VERSION ""

NS_ :

BS_:

BU_: CSDB CSDA HCM TSTR LDCMA LDCMB
VAL_TABLE_ Tracer_Turn_Actv 2 "SEQ B" 1 "SEQ A" 0 "Null" ;
VAL_TABLE_ Front_Fog_Actv 1 "Front Fog ON" 0 "Front Fog OFF" ;
VAL_TABLE_ Mdule1_Fail 1 "LDM is NOK" 0 "LDM is OK" ;
VAL_TABLE_ Hl_Temp_Stat 1 "HL over temperature " 0 "HL temperature OK" ;
VAL_TABLE_ HlHBSegFeedb 3 "At least one segment activated" 2 "Ramping up" 1 "Ramping down" 0 "All deactivated" ;
VAL_TABLE_ Low_Beam_state 1 "Low Beam Active" 0 "Default" ;
VAL_TABLE_ HeadLghtLvlRef_D_Rq 5 "Start partially reference 4" 4 "Start partially reference 3" 3 "Start partially reference 2" 2 "Lvl ref only" 1 "Start full rerence" 0 "No referencing action" ;
VAL_TABLE_ HeadLghtLvl_No_Rq 4095 "Faulty" ;
VAL_TABLE_ Quality_Flag 3 "OK" 2 "Not within specification" 1 "No Data exists" 0 "Faulty" ;
VAL_TABLE_ WfSubstate 5 "Approach" 4 "CourtesyLightDelay" 3 "DoorAjarCourtesyLights" 2 "IllExit" 1 "IllumEntry" 0 "NULL" ;
VAL_TABLE_ WfSuperstate 3 "FAREWELL" 2 "RUNSTART" 1 "WELCOME" 0 "OFF" ;
VAL_TABLE_ Hl_SM_Stat 1 "SM unit failure detected" 0 "SM unit status OK" ;
VAL_TABLE_ Hl_DRL_POS_Stat 1 "DRL_POS unit failure detected" 0 "DRL_POS unit status OK" ;
VAL_TABLE_ Hl_TI_Stat 1 "TI unit failure detected" 0 "TI unit status OK" ;
VAL_TABLE_ Hl_SBL_Stat 1 "SBL unit failure detected" 0 "SBL unit status OK" ;
VAL_TABLE_ Hl_Foregrd_Stat 1 "Foreground unit failure detected" 0 "Foreground unit status OK" ;
VAL_TABLE_ Hl_Pixel_Stat 1 "Pixel unit failure detected" 0 "Pixel unit status OK" ;
VAL_TABLE_ Hl_Fan_B_Stat 1 "Fan failure detected" 0 "Fan status OK" ;
VAL_TABLE_ Mdule1Hl_side_Stat 2 "LDM side detection failed." 1 "LDM detected right side." 0 "LDM detected left side." ;
VAL_TABLE_ Mdule1Hl_Com_Stat 1 "Physical CAN bus com lost" 0 "Physical CAN bus OK" ;
VAL_TABLE_ Mdule1_LB_Pwr_B_Stat 1 "LDM LB power supply power lost" 0 "LDM LB power supply available" ;
VAL_TABLE_ Mdule1_MPwr_B_Stat 1 "LDM main power supply power lost" 0 "LDM main power supply available." ;
VAL_TABLE_ DrlPos_Actv_Rq 2 "DRL intensity" 1 "POS intensity" 0 "OFF" ;
VAL_TABLE_ Turn_Actv_Rq 4 "ON Cycle sequential B" 3 "ON Cycle sequential A" 2 "ON Cycle" 1 "OFF Cycle" 0 "OFF" ;
VAL_TABLE_ Hlspot1_Rq 3 "Spot (only right side)" 2 "Spot (only left side)" 1 "Spot (both sides)" 0 "Not active" ;
VAL_TABLE_ HiBeamHWmde_SED_Rq 2 "Highway mode LHT" 1 "Highway mode RHT" 0 "No highway mode" ;
VAL_TABLE_ HllHBFeedb_D_Stat 4 "Spot (only right side)" 3 "Spot (only left side)" 2 "Spot (Both sides)" 1 "Full HB" 0 "HB off" ;
VAL_TABLE_ HB_D_Rq 6 "Spot (only right side)" 5 "Spot (only left side)" 4 "Spot (both sides)" 3 "Auto full highbeam" 2 "Manual full high beam" 1 "Flash to pass" 0 "No High beam" ;
VAL_TABLE_ TempStat 2 "Overtemperature" 1 "High Temperature" 0 "Status OK" ;
VAL_TABLE_ HlLevelStat 2 "Ref ongoing" 3 "Motor fail" 1 "Ref of stepper motors done" 0 "Ref of stepper motor necessary" ;
VAL_TABLE_ LvLRefRun_D_Req 5 "Start partially reference 4" 4 "Start partially reference 3" 3 "Start partially reference 2" 2 "Start partially reference 1" 1 "Start full rerence" 0 "No referencing action" ;
VAL_TABLE_ Sdlm_D_Rq 13 "Class W" 12 "Class E3" 11 "Class E2" 10 "Class E1" 9 "Class E" 8 "Class C4" 7 "Class C3" 6 "Class C2" 5 "Class C1" 4 "Class V1" 3 "Class V2" 2 "Class V3" 1 "Class V4" 0 "Class C" ;
VAL_TABLE_ MduleLeftFail_B_Stat 3 "Headlamp and LDM failure" 2 "Headlamp failure" 1 "LDM failure" 0 "OK" ;
VAL_TABLE_ MduleConfg_B_Stat 1 "FAULTY" 0 "OK" ;
VAL_TABLE_ HlSpotBrght_Pc_Rq 31 "Faulty" ;
VAL_TABLE_ HlSpotShape_D_Rq 15 "No valid signal" 14 "Shape 15" 13 "Shape 14" 12 "Shape 13" 11 "Shape 12" 10 "Shape 11" 9 "Shape 10" 8 "Shape 9" 7 "Shape 8" 6 "Shape 7" 5 "Shape 6" 4 "Shape 5" 3 "Shape 4" 2 "Shape 3" 1 "Shape 2" 0 "Shape 1" ;
VAL_TABLE_ DblTrgt_An_Rq 2047 "Faulty" ;
VAL_TABLE_ HlSpotTrgt_An_Rq 2047 "FAULT" ;
VAL_TABLE_ UnitlessValue12bit_IncldFaltET 4095 "Faulty" ;
VAL_TABLE_ Faulty_1F 31 "Faulty" ;
VAL_TABLE_ Faulty_7FF 2047 "Faulty" ;

BO_ 3221225472 VECTOR__INDEPENDENT_SIG_MSG: 0 Vector__XXX
 SG_ HeadLghtLvlRghtRef_D_Rq : 0|3@0+ (1,0) [0|7] "" Vector__XXX
 SG_ HeadLghtLvlLeftRef_D_Rq : 0|3@0+ (1,0) [0|7] "" Vector__XXX
 SG_ HeadLghtLvlRight_No_Rq : 0|12@0+ (1,0) [0|4095] "1/2 step" Vector__XXX
 SG_ HeadLghtLvlLeft_No_Rq : 0|12@0+ (1,0) [0|4095] "1/2 step" Vector__XXX
 SG_ HeadLghtDblRght_No_Stat : 0|12@0+ (1,0) [0|4095] "1/2 step" Vector__XXX
 SG_ HeadLghtDblLeft_No_Stat : 0|12@0+ (1,0) [0|4095] "1/2 step" Vector__XXX
 SG_ HeadLghtDblRight_No_Rq : 0|12@0+ (1,0) [0|4095] "1/2 step" Vector__XXX
 SG_ HeadLghtDblLeft_No_Rq : 0|12@0+ (1,0) [0|4095] "1/2 step" Vector__XXX
 SG_ Hlr_Foregrd_Stat : 0|1@0+ (1,0) [0|1] "" Vector__XXX
 SG_ Hll_Foregrd_Stat : 0|1@0+ (1,0) [0|1] "" Vector__XXX
 SG_ Tracer_Turn_Actv_Rq : 0|2@0+ (1,0) [0|3] "SED" Vector__XXX
 SG_ Turn_Deactv_Brght_Rq : 0|8@0+ (0.5,0) [0|100] "%" Vector__XXX
 SG_ LowBeam_Stat : 0|1@0+ (1,0) [0|1] "" Vector__XXX
 SG_ Turn_Actv_Rf_Rq : 0|2@0+ (1,0) [0|3] "" Vector__XXX
 SG_ Turn_Actv_Lf_Rq : 0|2@0+ (1,0) [0|3] "" Vector__XXX
 SG_ HeadLampLoFrOut_B_Stat : 0|1@0+ (1,0) [0|1] "SED" Vector__XXX
 SG_ TurnLampFrOut_B_Stat : 0|1@0+ (1,0) [0|1] "" Vector__XXX
 SG_ HeadLampLoFlOut_B_Stat : 0|1@0+ (1,0) [0|1] "SED" Vector__XXX
 SG_ TurnLampFlOut_B_Stat : 0|1@0+ (1,0) [0|1] "" Vector__XXX

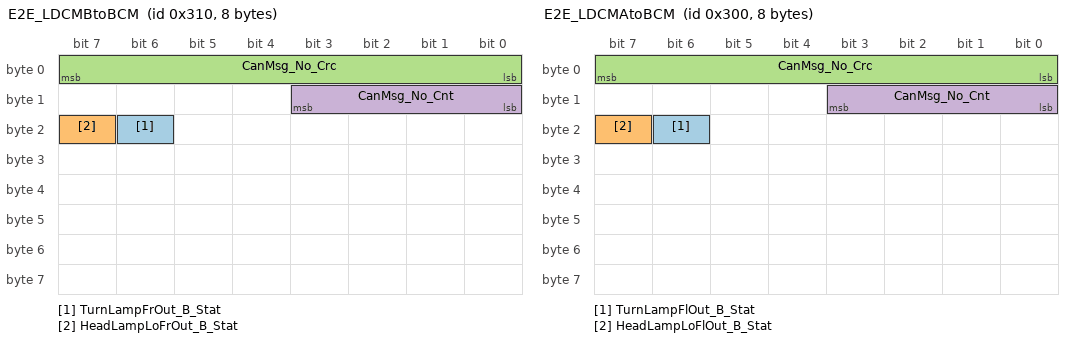
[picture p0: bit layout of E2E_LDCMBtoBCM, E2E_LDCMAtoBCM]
BO_ 784 E2E_LDCMBtoBCM: 8 LDCMB
 SG_ TurnLampFrOut_B_Stat : 22|1@0+ (1,0) [0|1] ""  HCM
 SG_ HeadLampLoFrOut_B_Stat : 23|1@0+ (1,0) [0|1] "SED"  HCM
 SG_ CanMsg_No_Crc : 7|8@0+ (1,0) [0|255] "Unitless" Vector__XXX
 SG_ CanMsg_No_Cnt : 11|4@0+ (1,0) [0|15] "Unitless" Vector__XXX

BO_ 768 E2E_LDCMAtoBCM: 8 LDCMA
 SG_ TurnLampFlOut_B_Stat : 22|1@0+ (1,0) [0|1] ""  HCM
 SG_ HeadLampLoFlOut_B_Stat : 23|1@0+ (1,0) [0|1] "SED"  HCM
 SG_ CanMsg_No_Crc : 7|8@0+ (1,0) [0|255] "Unitless" Vector__XXX
 SG_ CanMsg_No_Cnt : 11|4@0+ (1,0) [0|15] "Unitless" Vector__XXX

BO_ 1553 XCP_TSTRtoLDCMB: 8 TSTR
 SG_ XCP_TSTRtoLDCMB : 7|64@0+ (1,0) [0|1.84467E+019] "unitless"  LDCMB

BO_ 1552 XCP_TSTRtoLDCMA: 8 TSTR
 SG_ XCP_TSTRtoLDCMA : 7|64@0+ (1,0) [0|1.84467E+019] "unitless"  LDCMA

BO_ 1537 XCP_LDCMBtoTSTR: 8 LDCMB
 SG_ XCP_LDCMBtoTSTR : 7|64@0+ (1,0) [0|1.84467E+019] "unitless"  TSTR

BO_ 1536 XCP_LDCMAtoTSTR: 8 LDCMA
 SG_ XCP_LDCMAtoTSTR : 7|64@0+ (1,0) [0|1.84467E+019] "unitless"  TSTR

BO_ 2612224078 PARSEDPushLDCMBtoGWM_ECG: 8 LDCMB
 SG_ PARSEDPushLDCMBtoGWM_ECG : 7|29@0+ (1,0) [0|536870911] "unitless"  HCM

BO_ 2612082904 PARSEDPushFcGWM_ECGtoLDCMB: 8 HCM
 SG_ PARSEDPushFcGWM_ECGtoLDCMB : 7|29@0+ (1,0) [0|536870911] "unitless"  LDCMB

BO_ 2611175502 PARSEDPhysLDCMBtoGWM_ECG: 8 LDCMB
 SG_ PARSEDPhysLDCMBtoGWM_ECG : 7|29@0+ (1,0) [0|536870911] "unitless"  HCM

BO_ 2611034328 PARSEDPhysGWM_ECGtoLDCMB: 8 HCM
 SG_ PARSEDPhysGWM_ECGtoLDCMB : 7|29@0+ (1,0) [0|536870911] "unitless"  LDCMB

BO_ 2610126926 OTAPhysLDCMBtoGWM_ECG: 8 LDCMB
 SG_ OTAPhysLDCMBtoGWM_ECG : 7|29@0+ (1,0) [0|536870911] "unitless"  HCM

BO_ 2609985752 OTAPhysGWM_ECGtoLDCMB: 8 HCM
 SG_ OTAPhysGWM_ECGtoLDCMB : 7|29@0+ (1,0) [0|536870911] "unitless"  LDCMB

BO_ 2612224079 PARSEDPushLDCMAtoGWM_ECG: 8 LDCMA
 SG_ PARSEDPushLDCMAtoGWM_ECG : 7|29@0+ (1,0) [0|536870911] "unitless"  HCM

BO_ 1798 TesterPhysicalReqDev: 8 TSTR
 SG_ TesterPhysicalReqDev : 7|64@0+ (1,0) [0|1.84467E+019] "unitless"  CSDB,CSDA

BO_ 1806 TesterPhysicalResDev: 8 CSDA
 SG_ TesterPhysicalResDev : 7|64@0+ (1,0) [0|1.84467E+019] "unitless"  TSTR

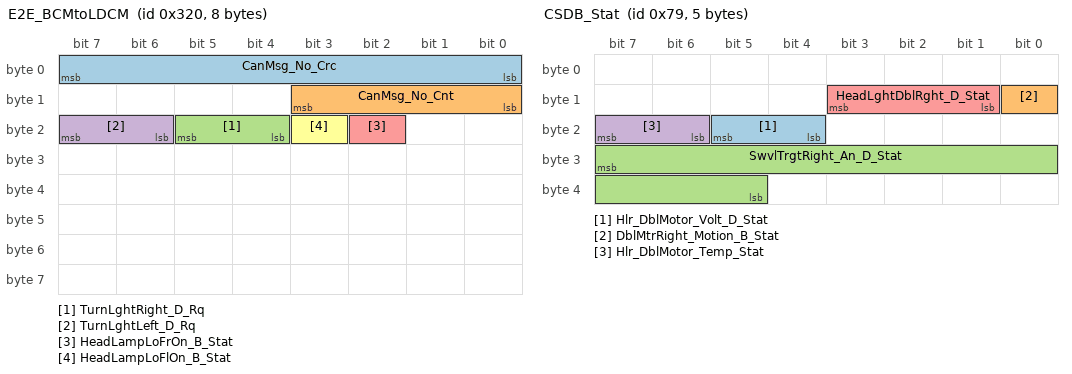
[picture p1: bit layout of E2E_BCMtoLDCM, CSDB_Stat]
BO_ 800 E2E_BCMtoLDCM: 8 HCM
 SG_ CanMsg_No_Crc : 7|8@0+ (1,0) [0|255] "Unitless" Vector__XXX
 SG_ CanMsg_No_Cnt : 11|4@0+ (1,0) [0|15] "Unitless" Vector__XXX
 SG_ TurnLghtRight_D_Rq : 21|2@0+ (1,0) [0|3] "SED"  LDCMA,LDCMB
 SG_ TurnLghtLeft_D_Rq : 23|2@0+ (1,0) [0|3] "SED"  LDCMB,LDCMA
 SG_ HeadLampLoFrOn_B_Stat : 18|1@0+ (1,0) [0|1] "SED"  LDCMA,LDCMB
 SG_ HeadLampLoFlOn_B_Stat : 19|1@0+ (1,0) [0|1] "SED"  LDCMB,LDCMA

BO_ 121 CSDB_Stat: 5 CSDB
 SG_ Hlr_DblMotor_Volt_D_Stat : 21|2@0+ (1,0) [0|3] "" Vector__XXX
 SG_ DblMtrRight_Motion_B_Stat : 8|1@0+ (1,0) [0|1] "" Vector__XXX
 SG_ SwvlTrgtRight_An_D_Stat : 31|11@0+ (0.04,-35) [-35|46.88] "Degrees" Vector__XXX
 SG_ Hlr_DblMotor_Temp_Stat : 23|2@0+ (1,0) [0|3] ""  HCM
 SG_ HeadLghtDblRght_D_Stat : 11|3@0+ (1,0) [0|7] "" Vector__XXX

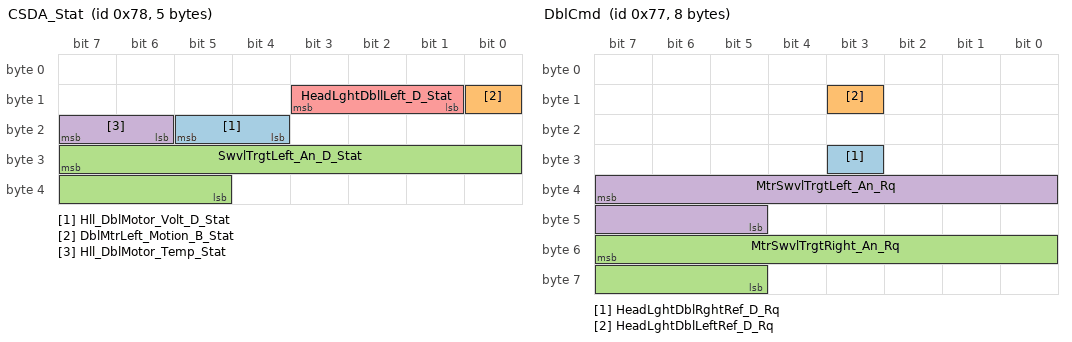
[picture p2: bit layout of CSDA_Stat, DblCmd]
BO_ 120 CSDA_Stat: 5 CSDA
 SG_ Hll_DblMotor_Volt_D_Stat : 21|2@0+ (1,0) [0|3] ""  HCM
 SG_ DblMtrLeft_Motion_B_Stat : 8|1@0+ (1,0) [0|1] "" Vector__XXX
 SG_ SwvlTrgtLeft_An_D_Stat : 31|11@0+ (0.04,-35) [-35|46.88] "Degrees" Vector__XXX
 SG_ Hll_DblMotor_Temp_Stat : 23|2@0+ (1,0) [0|3] "" Vector__XXX
 SG_ HeadLghtDbllLeft_D_Stat : 11|3@0+ (1,0) [0|7] "" Vector__XXX

BO_ 119 DblCmd: 8 HCM
 SG_ HeadLghtDblRghtRef_D_Rq : 27|1@0+ (1,0) [0|1] "" Vector__XXX
 SG_ HeadLghtDblLeftRef_D_Rq : 11|1@0+ (1,0) [0|1] "" Vector__XXX
 SG_ MtrSwvlTrgtRight_An_Rq : 55|11@0+ (0.04,-35) [-35|46.88] "Degrees"  CSDB
 SG_ MtrSwvlTrgtLeft_An_Rq : 39|11@0+ (0.04,-35) [-35|46.88] "Degrees"  CSDA

BO_ 1805 TesterPhysicalResCDSB: 8 CSDB
 SG_ TesterPhysicalResCDSB : 7|64@0+ (1,0) [0|1.84467E+019] "unitless"  TSTR

BO_ 1797 TesterPhysicalReqCDSB: 8 TSTR
 SG_ TesterPhysicalReqCDSB : 7|64@0+ (1,0) [0|1.84467E+019] "unitless"  CSDB

BO_ 1796 TesterPhysicalReqCDSA: 8 TSTR
 SG_ TesterPhysicalReqCDSA : 7|64@0+ (1,0) [0|1.84467E+019] "unitless"  CSDA

BO_ 1804 TesterPhysicalResCDSA: 8 CSDA
 SG_ TesterPhysicalResCDSA : 7|64@0+ (1,0) [0|1.84467E+019] "unitless"  TSTR

BO_ 2611035352 PARSEDPhysGWM_ECGtoLDCMA: 8 HCM
 SG_ PARSEDPhysGWM_ECGtoLDCMA : 7|29@0+ (1,0) [0|536870911] "unitless"  LDCMA

BO_ 2612083928 PARSEDPushFcGWM_ECGtoLDCMA: 8 HCM
 SG_ PARSEDPushFcGWM_ECGtoLDCMA : 7|29@0+ (1,0) [0|536870911] "unitless"  LDCMA

BO_ 2611175503 PARSEDPhysLDCMAtoGWM_ECG: 8 LDCMA
 SG_ PARSEDPhysLDCMAtoGWM_ECG : 7|29@0+ (1,0) [0|536870911] "unitless"  HCM

BO_ 2612002008 PARSEDFuncGWM_ECG_HCM: 8 HCM
 SG_ PARSEDFuncGWM_ECG : 7|29@0+ (1,0) [0|536870911] "unitless"  LDCMB,LDCMA

BO_ 2610126927 OTAPhysLDCMAtoGWM_ECG: 8 LDCMA
 SG_ OTAPhysLDCMAtoGWM_ECG : 7|29@0+ (1,0) [0|536870911] "unitless"  HCM

BO_ 2609986776 OTAPhysGWM_ECGtoLDCMA: 8 HCM
 SG_ OTAPhysGWM_ECGtoLDCMA : 7|29@0+ (1,0) [0|536870911] "unitless"  LDCMA

BO_ 2610953432 OTAFuncGWM_ECG_HCM: 8 HCM
 SG_ OTAFuncGWM_ECG : 7|29@0+ (1,0) [0|536870911] "unitless"  LDCMA,LDCMB

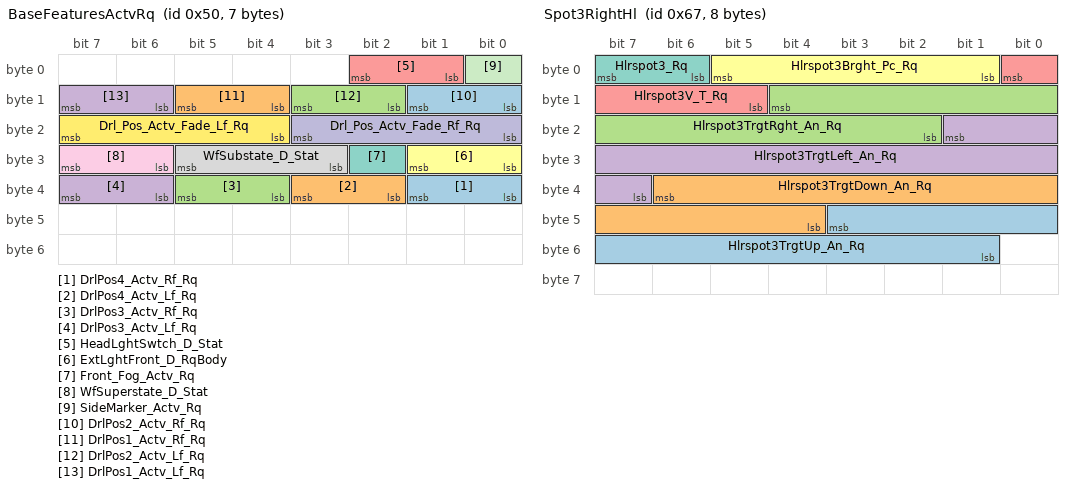
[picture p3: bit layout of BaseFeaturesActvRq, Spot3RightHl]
BO_ 80 BaseFeaturesActvRq: 7 HCM
 SG_ DrlPos4_Actv_Rf_Rq : 33|2@0+ (1,0) [0|3] " "  LDCMB,LDCMA
 SG_ DrlPos4_Actv_Lf_Rq : 35|2@0+ (1,0) [0|3] " "  LDCMB,LDCMA
 SG_ DrlPos3_Actv_Rf_Rq : 37|2@0+ (1,0) [0|3] " "  LDCMB,LDCMA
 SG_ DrlPos3_Actv_Lf_Rq : 39|2@0+ (1,0) [0|3] " "  LDCMB,LDCMA
 SG_ HeadLghtSwtch_D_Stat : 2|2@0+ (1,0) [0|3] " SED"  LDCMB,LDCMA
 SG_ ExtLghtFront_D_RqBody : 25|2@0+ (1,0) [0|3] ""  LDCMB,LDCMA
 SG_ Front_Fog_Actv_Rq : 26|1@0+ (1,0) [0|1] " SED"  LDCMA,LDCMB
 SG_ WfSubstate_D_Stat : 29|3@0+ (1,0) [0|7] ""  LDCMB,LDCMA
 SG_ WfSuperstate_D_Stat : 31|2@0+ (1,0) [0|3] ""  LDCMB,LDCMA
 SG_ Drl_Pos_Actv_Fade_Rf_Rq : 19|4@0+ (200,0) [0|3000] "ms"  LDCMB
 SG_ SideMarker_Actv_Rq : 0|1@0+ (1,0) [0|1] ""  LDCMB,LDCMA
 SG_ Drl_Pos_Actv_Fade_Lf_Rq : 23|4@0+ (200,0) [0|3000] "ms"  LDCMA
 SG_ DrlPos2_Actv_Rf_Rq : 9|2@0+ (1,0) [0|3] " "  LDCMA,LDCMB
 SG_ DrlPos1_Actv_Rf_Rq : 13|2@0+ (1,0) [0|3] " "  LDCMA,LDCMB
 SG_ DrlPos2_Actv_Lf_Rq : 11|2@0+ (1,0) [0|3] " "  LDCMB,LDCMA
 SG_ DrlPos1_Actv_Lf_Rq : 15|2@0+ (1,0) [0|3] " "  LDCMB,LDCMA

BO_ 103 Spot3RightHl: 8 HCM
 SG_ Hlrspot3TrgtUp_An_Rq : 43|11@0+ (0.04,-35) [-35|46.84] "degrees"  LDCMB
 SG_ Hlrspot3TrgtDown_An_Rq : 38|11@0+ (0.04,-35) [-35|46.84] "degrees"  LDCMB
 SG_ Hlrspot3TrgtRght_An_Rq : 12|11@0+ (0.04,-35) [-35|46.84] "degrees"  LDCMB
 SG_ Hlrspot3TrgtLeft_An_Rq : 17|11@0+ (0.04,-35) [-35|46.84] "degrees"  LDCMB
 SG_ Hlrspot3V_T_Rq : 0|4@0+ (200,0) [0|3000] "ms"  LDCMB
 SG_ Hlrspot3Brght_Pc_Rq : 5|5@0+ (3.5,0) [0|105] "percent"  LDCMB
 SG_ Hlrspot3_Rq : 7|2@0+ (1,0) [0|0] ""  LDCMB

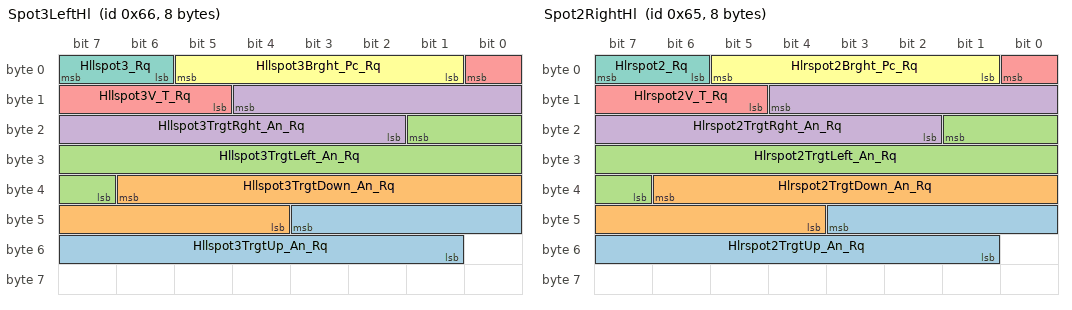
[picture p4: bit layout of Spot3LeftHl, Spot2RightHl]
BO_ 102 Spot3LeftHl: 8 HCM
 SG_ Hllspot3TrgtUp_An_Rq : 43|11@0+ (0.04,-35) [-35|46.84] "degrees"  LDCMA
 SG_ Hllspot3TrgtDown_An_Rq : 38|11@0+ (0.04,-35) [-35|46.84] "degrees"  LDCMA
 SG_ Hllspot3TrgtLeft_An_Rq : 17|11@0+ (0.04,-35) [-35|46.84] "degrees"  LDCMA
 SG_ Hllspot3TrgtRght_An_Rq : 12|11@0+ (0.04,-35) [-35|46.84] "degrees"  LDCMA
 SG_ Hllspot3V_T_Rq : 0|4@0+ (200,0) [0|3000] "ms"  LDCMA
 SG_ Hllspot3Brght_Pc_Rq : 5|5@0+ (3.5,0) [0|105] "percent"  LDCMA
 SG_ Hllspot3_Rq : 7|2@0+ (1,0) [0|3] ""  LDCMA

BO_ 101 Spot2RightHl: 8 HCM
 SG_ Hlrspot2TrgtUp_An_Rq : 43|11@0+ (0.04,-35) [-35|46.84] "degrees"  LDCMB
 SG_ Hlrspot2TrgtDown_An_Rq : 38|11@0+ (0.04,-35) [-35|46.84] "degrees"  LDCMB
 SG_ Hlrspot2TrgtLeft_An_Rq : 17|11@0+ (0.04,-35) [-35|46.84] "degrees"  LDCMB
 SG_ Hlrspot2TrgtRght_An_Rq : 12|11@0+ (0.04,-35) [-35|46.84] "degrees"  LDCMB
 SG_ Hlrspot2V_T_Rq : 0|4@0+ (200,0) [0|3000] "ms"  LDCMB
 SG_ Hlrspot2Brght_Pc_Rq : 5|5@0+ (3.5,0) [0|105] "percent"  LDCMB
 SG_ Hlrspot2_Rq : 7|2@0+ (1,0) [0|0] ""  LDCMB

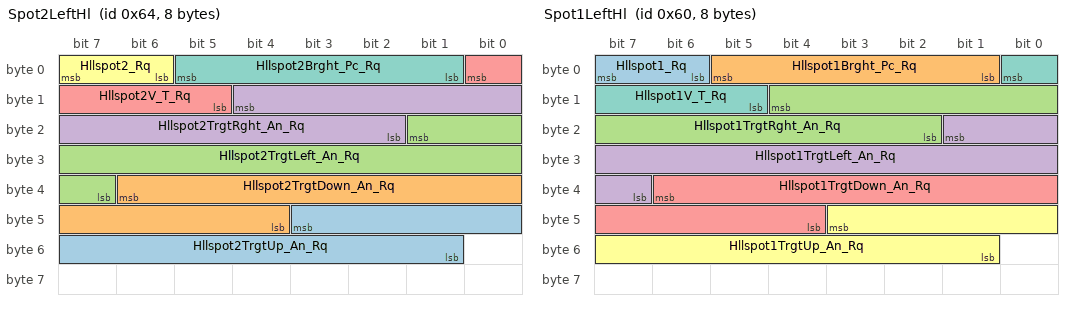
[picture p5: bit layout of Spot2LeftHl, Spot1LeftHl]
BO_ 100 Spot2LeftHl: 8 HCM
 SG_ Hllspot2TrgtUp_An_Rq : 43|11@0+ (0.04,-35) [-35|46.84] "degrees"  LDCMA
 SG_ Hllspot2TrgtDown_An_Rq : 38|11@0+ (0.04,-35) [-35|46.84] "degrees"  LDCMA
 SG_ Hllspot2TrgtLeft_An_Rq : 17|11@0+ (0.04,-35) [-35|46.84] "degrees"  LDCMA
 SG_ Hllspot2TrgtRght_An_Rq : 12|11@0+ (0.04,-35) [-35|46.84] "degrees"  LDCMA
 SG_ Hllspot2V_T_Rq : 0|4@0+ (200,0) [0|3000] "ms"  LDCMA
 SG_ Hllspot2_Rq : 7|2@0+ (1,0) [0|3] ""  LDCMA
 SG_ Hllspot2Brght_Pc_Rq : 5|5@0+ (3.5,0) [0|105] "percent"  LDCMA

BO_ 2015 TesterFunctionalReq_HCM: 8 TSTR
 SG_ TesterFunctionalReq : 7|64@0+ (1,0) [0|1.84467E+019] "unitless"  LDCMA,LDCMB

BO_ 1791 TesterPhysicalResLDCMB: 8 LDCMB
 SG_ TesterPhysicalResLDCMB : 7|64@0+ (1,0) [0|1.84467E+019] "unitless"  TSTR,HCM

BO_ 1790 TesterPhysicalResLDCMA: 8 LDCMA
 SG_ TesterPhysicalResLDCMA : 7|64@0+ (1,0) [0|1.84467E+019] "unitless"  TSTR,HCM

BO_ 1783 TesterPhysicalReqLDCMB: 8 TSTR
 SG_ TesterPhysicalReqLDCMB : 7|64@0+ (1,0) [0|1.84467E+019] "unitless"  LDCMB

BO_ 1782 TesterPhysicalReqLDCMA: 8 TSTR
 SG_ TesterPhysicalReqLDCMA : 7|64@0+ (1,0) [0|1.84467E+019] "unitless"  LDCMA

BO_ 96 Spot1LeftHl: 8 HCM
 SG_ Hllspot1_Rq : 7|2@0+ (1,0) [0|3] ""  LDCMA
 SG_ Hllspot1Brght_Pc_Rq : 5|5@0+ (3.5,0) [0|108.5] "percent"  LDCMA
 SG_ Hllspot1TrgtRght_An_Rq : 12|11@0+ (0.04,-35) [-35|46.84] "degrees"  LDCMA
 SG_ Hllspot1TrgtLeft_An_Rq : 17|11@0+ (0.04,-35) [-35|46.84] "degrees"  LDCMA
 SG_ Hllspot1TrgtDown_An_Rq : 38|11@0+ (0.04,-35) [-35|46.84] "degrees"  LDCMA
 SG_ Hllspot1TrgtUp_An_Rq : 43|11@0+ (0.04,-35) [-35|46.84] "degrees"  LDCMA
 SG_ Hllspot1V_T_Rq : 0|4@0+ (200,0) [0|3000] "ms"  LDCMA

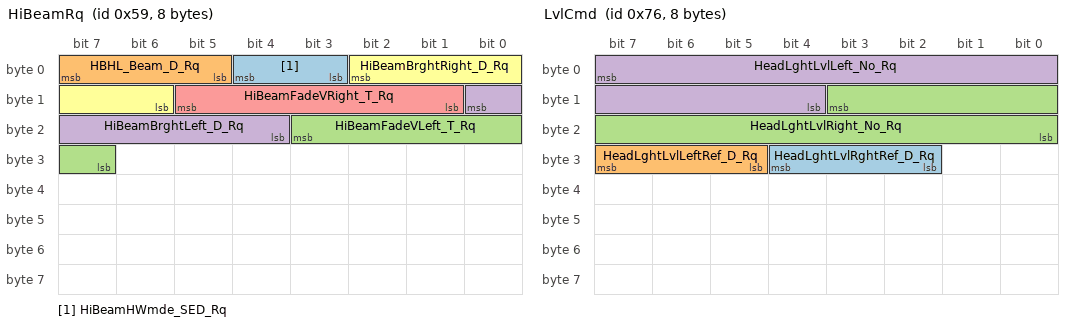
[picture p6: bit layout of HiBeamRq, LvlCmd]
BO_ 89 HiBeamRq: 8 HCM
 SG_ HiBeamHWmde_SED_Rq : 4|2@0+ (1,0) [0|3] ""  LDCMA,LDCMB
 SG_ HBHL_Beam_D_Rq : 7|3@0+ (1,0) [0|7] ""  LDCMA,LDCMB
 SG_ HiBeamFadeVLeft_T_Rq : 19|5@0+ (200,0) [0|6200] "ms"  LDCMA,LDCMB
 SG_ HiBeamBrghtLeft_D_Rq : 8|5@0+ (3.5,0) [0|108.5] "%"  LDCMA,LDCMB
 SG_ HiBeamFadeVRight_T_Rq : 13|5@0+ (200,0) [0|6200] "ms"  LDCMA,LDCMB
 SG_ HiBeamBrghtRight_D_Rq : 2|5@0+ (3.5,0) [0|108.5] "%"  LDCMA,LDCMB

BO_ 117 HlStatFR1: 7 LDCMB
 SG_ HlrHBFeedb_D_Stat : 16|3@0+ (1,0) [0|7] "" Vector__XXX
 SG_ HlLoFrOnfdbck_B_Stat : 8|1@0+ (1,0) [0|1] "SED"  HCM
 SG_ HlrHBSegFeedb_D_Stat : 18|2@0+ (1,0) [0|3] ""  HCM
 SG_ Hlr_Temp_Stat : 4|1@0+ (1,0) [0|1] ""  HCM
 SG_ Mdule1RightHl_side_Stat : 3|2@0+ (1,0) [0|3] ""  HCM
 SG_ Mdule1RightHl_Com_Stat : 5|1@0+ (1,0) [0|1] ""  HCM
 SG_ Mdule1Right_MPwr_B_Stat : 6|1@0+ (1,0) [0|1] ""  HCM
 SG_ Mdule1Right_LB_Pwr_B_Stat : 7|1@0+ (1,0) [0|1] ""  HCM
 SG_ Hlr_SM_Stat : 13|1@0+ (1,0) [0|1] ""  HCM
 SG_ Hlr_SBL_Stat : 14|1@0+ (1,0) [0|1] ""  HCM
 SG_ Hlr_Pixel_Stat : 12|1@0+ (1,0) [0|1] ""  HCM
 SG_ Hlr_Fan_B_Stat : 15|1@0+ (1,0) [0|1] ""  HCM
 SG_ Hlr_DRL_POS_Stat : 11|1@0+ (1,0) [0|1] ""  HCM
 SG_ Hlr_LvlMotor_Temp_Stat : 23|2@0+ (1,0) [0|3] ""  HCM
 SG_ HeadLghtLvlRght_D_Stat : 21|3@0+ (1,0) [0|7] ""  HCM
 SG_ HeadLghtLvlRght_No_Stat : 29|12@0+ (1,0) [0|4095] "1/2 step"  HCM
 SG_ Mdule1RightFail_B_Stat : 1|1@0+ (1,0) [0|1] ""  HCM
 SG_ Mdule1RightConfg_B_Stat : 0|1@0+ (1,0) [0|1] ""  HCM

BO_ 116 HlStatFL1: 8 LDCMA
 SG_ HllHBFeedb_D_Stat : 16|3@0+ (1,0) [0|7] "" Vector__XXX
 SG_ HlLoFlOnfdbck_B_Stat : 8|1@0+ (1,0) [0|1] "SED"  HCM
 SG_ HeadLghtLvlLeft_No_Stat : 29|12@0+ (1,0) [0|4095] "1/2 step"  HCM
 SG_ HllHBSegFeedb_D_Stat : 18|2@0+ (1,0) [0|3] ""  HCM
 SG_ Hll_Temp_Stat : 4|1@0+ (1,0) [0|1] ""  HCM
 SG_ Mdule1LeftHl_side_Stat : 3|2@0+ (1,0) [0|3] ""  HCM
 SG_ Mdule1LeftHl_Com_Stat : 5|1@0+ (1,0) [0|1] ""  HCM
 SG_ Mdule1Left_MPwr_B_Stat : 6|1@0+ (1,0) [0|1] ""  HCM
 SG_ Mdule1Left_LB_Pwr_B_Stat : 7|1@0+ (1,0) [0|1] ""  HCM
 SG_ Hll_SM_Stat : 13|1@0+ (1,0) [0|1] ""  HCM
 SG_ Hll_SBL_Stat : 14|1@0+ (1,0) [0|1] ""  HCM
 SG_ Hll_Pixel_Stat : 12|1@0+ (1,0) [0|1] ""  HCM
 SG_ Hll_Fan_B_Stat : 15|1@0+ (1,0) [0|1] ""  HCM
 SG_ Hll_DRL_POS_Stat : 11|1@0+ (1,0) [0|1] ""  HCM
 SG_ Hll_LvlMotor_Temp_Stat : 23|2@0+ (1,0) [0|3] ""  HCM
 SG_ HeadLghtLvlLeft_D_Stat : 21|3@0+ (1,0) [0|7] ""  HCM
 SG_ Mdule1LeftFail_B_Stat : 1|1@0+ (1,0) [0|1] ""  HCM
 SG_ Mdule1LeftConfg_B_Stat : 0|1@0+ (1,0) [0|1] ""  HCM

BO_ 118 LvlCmd: 8 HCM
 SG_ HeadLghtLvlRghtRef_D_Rq : 28|3@0+ (1,0) [0|7] ""  LDCMB
 SG_ HeadLghtLvlLeftRef_D_Rq : 31|3@0+ (1,0) [0|7] ""  LDCMA
 SG_ HeadLghtLvlRight_No_Rq : 11|12@0+ (1,0) [0|4095] "1/2 step"  LDCMB
 SG_ HeadLghtLvlLeft_No_Rq : 7|12@0+ (1,0) [0|4095] "1/2 step"  LDCMA

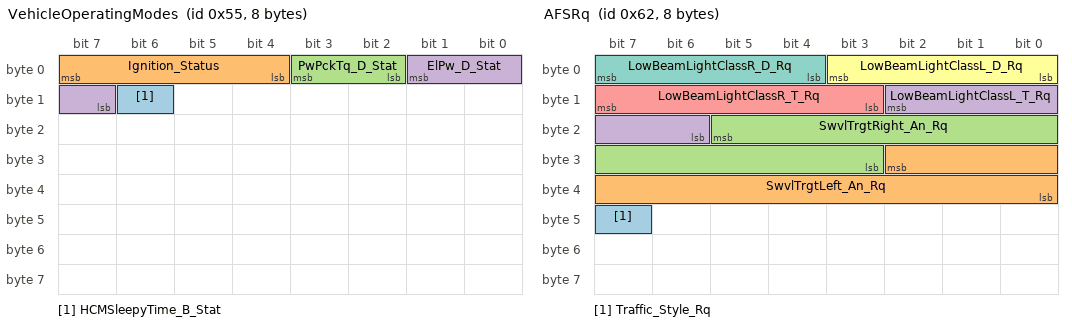
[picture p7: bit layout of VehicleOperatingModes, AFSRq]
BO_ 85 VehicleOperatingModes: 8 HCM
 SG_ HCMSleepyTime_B_Stat : 14|1@0+ (1,0) [0|1] ""  LDCMB,LDCMA
 SG_ Ignition_Status : 7|4@0+ (1,0) [0|15] ""  LDCMA,LDCMB
 SG_ PwPckTq_D_Stat : 3|2@0+ (1,0) [0|3] ""  LDCMA,LDCMB
 SG_ ElPw_D_Stat : 1|3@0+ (1,0) [0|7] "SED"  LDCMA,LDCMB

BO_ 98 AFSRq: 8 HCM
 SG_ Traffic_Style_Rq : 47|1@0+ (1,0) [0|1] ""  LDCMA,LDCMB
 SG_ SwvlTrgtLeft_An_Rq : 26|11@0+ (0.04,-35) [-35|46.88] "Degrees"  LDCMA,LDCMB
 SG_ SwvlTrgtRight_An_Rq : 21|11@0+ (0.04,-35) [-35|46.88] "Degrees"  LDCMA,LDCMB
 SG_ LowBeamLightClassL_T_Rq : 10|5@0+ (200,0) [0|6200] "ms"  LDCMA,LDCMB
 SG_ LowBeamLightClassR_T_Rq : 15|5@0+ (200,0) [0|6200] "ms"  LDCMA,LDCMB
 SG_ LowBeamLightClassL_D_Rq : 3|4@0+ (1,0) [0|15] ""  LDCMA,LDCMB
 SG_ LowBeamLightClassR_D_Rq : 7|4@0+ (1,0) [0|15] ""  LDCMA,LDCMB

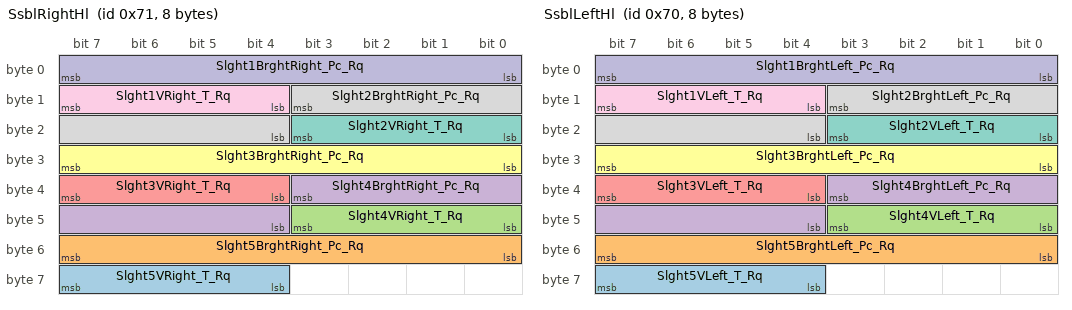
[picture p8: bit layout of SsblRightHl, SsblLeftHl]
BO_ 113 SsblRightHl: 8 HCM
 SG_ Slght5VRight_T_Rq : 63|4@0+ (500,0) [0|7500] "ms"  LDCMB
 SG_ Slght5BrghtRight_Pc_Rq : 55|8@0+ (0.5,0) [0|100] "%"  LDCMB
 SG_ Slght4VRight_T_Rq : 43|4@0+ (500,0) [0|7500] "ms"  LDCMB
 SG_ Slght4BrghtRight_Pc_Rq : 35|8@0+ (0.5,0) [0|100] "%"  LDCMB
 SG_ Slght3VRight_T_Rq : 39|4@0+ (500,0) [0|7500] "ms"  LDCMB
 SG_ Slght3BrghtRight_Pc_Rq : 31|8@0+ (0.5,0) [0|100] "%"  LDCMB
 SG_ Slght2VRight_T_Rq : 19|4@0+ (500,0) [0|7500] "ms"  LDCMB
 SG_ Slght2BrghtRight_Pc_Rq : 11|8@0+ (0.5,0) [0|100] "%"  LDCMB
 SG_ Slght1VRight_T_Rq : 15|4@0+ (500,0) [0|7500] "ms"  LDCMB
 SG_ Slght1BrghtRight_Pc_Rq : 7|8@0+ (0.5,0) [0|100] "%"  LDCMB

BO_ 112 SsblLeftHl: 8 HCM
 SG_ Slght5VLeft_T_Rq : 63|4@0+ (500,0) [0|7500] "ms"  LDCMA
 SG_ Slght5BrghtLeft_Pc_Rq : 55|8@0+ (0.5,0) [0|100] "%"  LDCMA
 SG_ Slght4VLeft_T_Rq : 43|4@0+ (500,0) [0|7500] "ms"  LDCMA
 SG_ Slght4BrghtLeft_Pc_Rq : 35|8@0+ (0.5,0) [0|100] "%"  LDCMA
 SG_ Slght3VLeft_T_Rq : 39|4@0+ (500,0) [0|7500] "ms"  LDCMA
 SG_ Slght3BrghtLeft_Pc_Rq : 31|8@0+ (0.5,0) [0|100] "%"  LDCMA
 SG_ Slght2VLeft_T_Rq : 19|4@0+ (500,0) [0|7500] "ms"  LDCMA
 SG_ Slght2BrghtLeft_Pc_Rq : 11|8@0+ (0.5,0) [0|100] "%"  LDCMA
 SG_ Slght1VLeft_T_Rq : 15|4@0+ (500,0) [0|7500] "ms"  LDCMA
 SG_ Slght1BrghtLeft_Pc_Rq : 7|8@0+ (0.5,0) [0|100] "%"  LDCMA

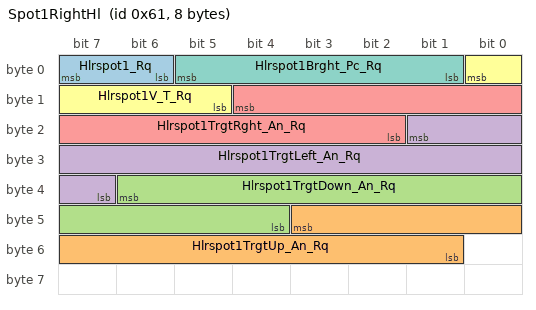
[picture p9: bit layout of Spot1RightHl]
BO_ 97 Spot1RightHl: 8 HCM
 SG_ Hlrspot1_Rq : 7|2@0+ (1,0) [0|3] ""  LDCMB
 SG_ Hlrspot1TrgtUp_An_Rq : 43|11@0+ (0.04,-35) [-35|46.84] "degrees"  LDCMB
 SG_ Hlrspot1TrgtDown_An_Rq : 38|11@0+ (0.04,-35) [-35|46.84] "degrees"  LDCMB
 SG_ Hlrspot1TrgtLeft_An_Rq : 17|11@0+ (0.04,-35) [-35|46.84] "degrees"  LDCMB
 SG_ Hlrspot1TrgtRght_An_Rq : 12|11@0+ (0.04,-35) [-35|46.84] "degrees"  LDCMB
 SG_ Hlrspot1V_T_Rq : 0|4@0+ (200,0) [0|3000] "ms"  LDCMB
 SG_ Hlrspot1Brght_Pc_Rq : 5|5@0+ (3.5,0) [0|108.5] "percent"  LDCMB

BO_TX_BU_ 2015 : HCM,TSTR;
BO_TX_BU_ 1783 : HCM,TSTR;
BO_TX_BU_ 1782 : HCM,TSTR;

CM_ "HCM Private CAN Network";
CM_ BU_ LDCMA "Lighting Driver Control Module “A” - Left Side LDM";
CM_ BU_ LDCMB "Lighting Driver Control Module “B” - Right Side LDM";
CM_ BO_ 3221225472 "This is a message for not used signals, created by Vector CANdb++ DBC OLE DB Provider.";
CM_ SG_ 3221225472 HeadLghtLvlRghtRef_D_Rq "Command to start referencing run including leveling and beam shape changes. ";
CM_ SG_ 3221225472 HeadLghtLvlLeftRef_D_Rq "Command to start referencing run including leveling and beam shape changes. ";
CM_ SG_ 3221225472 HeadLghtLvlRight_No_Rq "Command to move leveling. Given in half  steps.";
CM_ SG_ 3221225472 HeadLghtLvlLeft_No_Rq "Command to move leveling. Given in half steps.";
CM_ SG_ 3221225472 HeadLghtDblRght_No_Stat "Command to move leveling. Given in quarter steps.";
CM_ SG_ 3221225472 HeadLghtDblLeft_No_Stat "Command to move leveling. Given in quarter steps.";
CM_ SG_ 3221225472 HeadLghtDblRight_No_Rq "Command to move leveling. Given in half  steps.";
CM_ SG_ 3221225472 HeadLghtDblLeft_No_Rq "Command to move leveling. Given in half steps.";
CM_ SG_ 3221225472 Hlr_Foregrd_Stat "Provide Foreground unit status. Triger Foreground general electircal failure DTC";
CM_ SG_ 3221225472 Hll_Foregrd_Stat "Provide Foreground unit status. Triger Foreground general electircal failure DTC";
CM_ SG_ 3221225472 Tracer_Turn_Actv_Rq "Sequential TI control signal.";
CM_ SG_ 3221225472 LowBeam_Stat "Status of LB function. Information/Status only.";
CM_ SG_ 3221225472 Turn_Actv_Rf_Rq "Front Right Turn Indicator activation control.";
CM_ SG_ 3221225472 Turn_Actv_Lf_Rq "Front Left Turn Indicator activation control.";
CM_ SG_ 3221225472 TurnLampFrOut_B_Stat "Provide TI unit status. Trigger TI feedback to BCM and TI general electircal failure DTC";
CM_ SG_ 3221225472 TurnLampFlOut_B_Stat "Provide TI unit status. Trigger TI feedback to BCM and TI general electircal failure DTC";
CM_ SG_ 784 TurnLampFrOut_B_Stat "Provide TI unit status. Trigger TI feedback to BCM and TI general electircal failure DTC";
CM_ SG_ 784 CanMsg_No_Crc "E2E Protection CRC";
CM_ SG_ 768 TurnLampFlOut_B_Stat "Provide TI unit status. Trigger TI feedback to BCM and TI general electircal failure DTC";
CM_ SG_ 768 CanMsg_No_Crc "E2E Protection CRC";
CM_ BO_ 800 "HS2/FD1 origin LB command ";
CM_ SG_ 800 CanMsg_No_Crc "E2E Protection CRC";
CM_ SG_ 800 TurnLghtRight_D_Rq "Turn Request Command for Right Turn Indicator";
CM_ SG_ 800 TurnLghtLeft_D_Rq "Turn Request Command for Left Turn Indicator";
CM_ BO_ 121 "Message to transmit the status of the front right headlamp in regards to leveling, LED outage, LDM status";
CM_ SG_ 121 Hlr_DblMotor_Volt_D_Stat "Determing stepper motor voltage status";
CM_ SG_ 121 DblMtrRight_Motion_B_Stat "Feedback to indicate actual moving status of DBL motor";
CM_ SG_ 121 SwvlTrgtRight_An_D_Stat "Dynamic bending light target angle command right headlamp";
CM_ SG_ 121 Hlr_DblMotor_Temp_Stat "Determing stepper motor temperature status";
CM_ SG_ 121 HeadLghtDblRght_D_Stat "Command to start referencing run including leveling and beam shape changes. ";
CM_ BO_ 120 "Message to transmit the status of the front left headlamp in regards to leveling, LED outage, LDM status";
CM_ SG_ 120 Hll_DblMotor_Volt_D_Stat "Determing stepper motor voltage status";
CM_ SG_ 120 DblMtrLeft_Motion_B_Stat "Feedback to indicate actual moving status of DBL motor";
CM_ SG_ 120 SwvlTrgtLeft_An_D_Stat "Dynamic bending light target angle command left headlamp";
CM_ SG_ 120 Hll_DblMotor_Temp_Stat "Determing stepper motor temperature status";
CM_ SG_ 120 HeadLghtDbllLeft_D_Stat "Command to start referencing run including leveling and beam shape changes. ";
CM_ BO_ 119 "Message for headlamp leveling target data and headlamp reference run for leveling, swiveling and light modes";
CM_ SG_ 119 HeadLghtDblRghtRef_D_Rq "Command to start referencing run including leveling and beam shape changes. ";
CM_ SG_ 119 HeadLghtDblLeftRef_D_Rq "Command to start referencing run including leveling and beam shape changes. ";
CM_ SG_ 119 MtrSwvlTrgtRight_An_Rq "Dynamic bending light target angle command right headlamp. In a default configuration, a positive angle command denotes a movement to the left from the driver's point of view.";
CM_ SG_ 119 MtrSwvlTrgtLeft_An_Rq "Dynamic bending light target angle command left headlamp. In a default configuration, a positive angle command denotes a movement to the left from the driver's point of view.";
CM_ BO_ 80 "Base Lighting Feature Control";
CM_ SG_ 80 DrlPos4_Actv_Rf_Rq "Right DRL and POS activation control of second part of the string";
CM_ SG_ 80 DrlPos4_Actv_Lf_Rq "Left DRL and POS activation control of second part of the string";
CM_ SG_ 80 DrlPos3_Actv_Rf_Rq "Right DRL and POS activation control of first part of the string";
CM_ SG_ 80 DrlPos3_Actv_Lf_Rq "Left DRL and POS activation control of first part of the string";
CM_ SG_ 80 HeadLghtSwtch_D_Stat "Current headlamp switch status";
CM_ SG_ 80 ExtLghtFront_D_RqBody "Tourist mode. 
0x01 changes the vehicle default beam shape to the opposite. 
Default beam shape is dependant on the traffic side the vehicle has been licensed to";
CM_ SG_ 80 Front_Fog_Actv_Rq "Front Fog activation request.";
CM_ SG_ 80 WfSubstate_D_Stat "Welcome Farewell Substate";
CM_ SG_ 80 WfSuperstate_D_Stat "Welcome Farewell Superstate";
CM_ SG_ 80 Drl_Pos_Actv_Fade_Rf_Rq "DRL and POS activation fading time in ms/100% for right headlamp";
CM_ SG_ 80 SideMarker_Actv_Rq "Status of LB function. Information/Status only.";
CM_ SG_ 80 Drl_Pos_Actv_Fade_Lf_Rq "DRL and POS activation fading time in ms/100% for left headlamp";
CM_ SG_ 80 DrlPos2_Actv_Rf_Rq "Right DRL and POS activation control of second part of the string";
CM_ SG_ 80 DrlPos1_Actv_Rf_Rq "Right DRL and POS activation control of first part of the string";
CM_ SG_ 80 DrlPos2_Actv_Lf_Rq "Left DRL and POS activation control of second part of the string";
CM_ SG_ 80 DrlPos1_Actv_Lf_Rq "Left DRL and POS activation control of first part of the string";
CM_ BO_ 103 "Message for right headlamp describing the spot for GFHB/ ADB feature";
CM_ SG_ 103 Hlrspot3TrgtUp_An_Rq "Target angle of the spot given an imaginary rectangle from the current vehicle H-H line (horizon)";
CM_ SG_ 103 Hlrspot3TrgtDown_An_Rq "Target angle of the spot given an imaginary rectangle from the current vehicle H-H line (horizon)";
CM_ SG_ 103 Hlrspot3TrgtRght_An_Rq "Target angle of the spot given an imaginary rectangle from the current vehicle H-H line (horizon)";
CM_ SG_ 103 Hlrspot3TrgtLeft_An_Rq "Target angle of the spot given an imaginary rectangle from the current vehicle H-H line (horizon)";
CM_ SG_ 103 Hlrspot3V_T_Rq "Theatre fading speed command to HighBeamSpot. Time is defining [ms/0% activation]";
CM_ SG_ 103 Hlrspot3Brght_Pc_Rq "Brightness command to HighBeamSpot for right headlamp Spot";
CM_ SG_ 103 Hlrspot3_Rq "Spot request";
CM_ BO_ 102 "Message for left headlamp describing the spot for GFHB/ ADB feature";
CM_ SG_ 102 Hllspot3TrgtUp_An_Rq "Target angle of the spot given an imaginary rectangle from the current vehicle H-H line (horizon)";
CM_ SG_ 102 Hllspot3TrgtDown_An_Rq "Target angle of the spot given an imaginary rectangle from the current vehicle H-H line (horizon)";
CM_ SG_ 102 Hllspot3TrgtLeft_An_Rq "Target angle of the spot given an imaginary rectangle from the current vehicle H-H line (horizon)";
CM_ SG_ 102 Hllspot3TrgtRght_An_Rq "Target angle of the spot given an imaginary rectangle from the current vehicle H-H line (horizon)";
CM_ SG_ 102 Hllspot3V_T_Rq "Theatre fading speed command to HighBeamSpot. Time is defining [ms/0% activation]";
CM_ SG_ 102 Hllspot3Brght_Pc_Rq "Brightness command to HighBeamSpot for left headlamp Spot";
CM_ SG_ 102 Hllspot3_Rq "Spot request";
CM_ BO_ 101 "Message for right headlamp describing the spot for GFHB/ ADB feature";
CM_ SG_ 101 Hlrspot2TrgtUp_An_Rq "Target angle of the spot given an imaginary rectangle from the current vehicle H-H line (horizon)";
CM_ SG_ 101 Hlrspot2TrgtDown_An_Rq "Target angle of the spot given an imaginary rectangle from the current vehicle H-H line (horizon)";
CM_ SG_ 101 Hlrspot2TrgtLeft_An_Rq "Target angle of the spot given an imaginary rectangle from the current vehicle H-H line (horizon)";
CM_ SG_ 101 Hlrspot2TrgtRght_An_Rq "Target angle of the spot given an imaginary rectangle from the current vehicle H-H line (horizon)";
CM_ SG_ 101 Hlrspot2V_T_Rq "Theatre fading speed command to HighBeamSpot. Time is defining [ms/0% activation]";
CM_ SG_ 101 Hlrspot2Brght_Pc_Rq "Brightness command to HighBeamSpot for right headlamp Spot";
CM_ SG_ 101 Hlrspot2_Rq "Spot request";
CM_ BO_ 100 "Message for left headlamp describing the spot for GFHB/ ADB feature";
CM_ SG_ 100 Hllspot2TrgtUp_An_Rq "Target angle of the spot given an imaginary rectangle from the current vehicle H-H line (horizon)";
CM_ SG_ 100 Hllspot2TrgtDown_An_Rq "Target angle of the spot given an imaginary rectangle from the current vehicle H-H line (horizon)";
CM_ SG_ 100 Hllspot2TrgtLeft_An_Rq "Target angle of the spot given an imaginary rectangle from the current vehicle H-H line (horizon)";
CM_ SG_ 100 Hllspot2TrgtRght_An_Rq "Target angle of the spot given an imaginary rectangle from the current vehicle H-H line (horizon)";
CM_ SG_ 100 Hllspot2V_T_Rq "Theatre fading speed command to HighBeamSpot. Time is defining [ms/0% activation]";
CM_ SG_ 100 Hllspot2_Rq "Spot request";
CM_ SG_ 100 Hllspot2Brght_Pc_Rq "Brightness command to HighBeamSpot for left headlamp Spot";
CM_ BO_ 96 "Message for left headlamp describing the spot for GFHB/ ADB feature";
CM_ SG_ 96 Hllspot1_Rq "Spot request";
CM_ SG_ 96 Hllspot1Brght_Pc_Rq "Brightness command to HighBeamSpot for left headlamp Spot";
CM_ SG_ 96 Hllspot1TrgtRght_An_Rq "Target angle of the spot given an imaginary rectangle from the current vehicle H-H line (horizon)";
CM_ SG_ 96 Hllspot1TrgtLeft_An_Rq "Target angle of the spot given an imaginary rectangle from the current vehicle H-H line (horizon)";
CM_ SG_ 96 Hllspot1TrgtDown_An_Rq "Target angle of the spot given an imaginary rectangle from the current vehicle H-H line (horizon)";
CM_ SG_ 96 Hllspot1TrgtUp_An_Rq "Target angle of the spot given an imaginary rectangle from the current vehicle H-H line (horizon)";
CM_ SG_ 96 Hllspot1V_T_Rq "Theatre fading speed command to HighBeamSpot. Time is defining [ms/0% activation]";
CM_ BO_ 89 "High beam request for manual/Auto/GFHB/ADB high beam";
CM_ SG_ 89 HBHL_Beam_D_Rq "High beam request and mode";
CM_ SG_ 89 HiBeamFadeVLeft_T_Rq "Theatre fading speed command to HighBeam. Time is defining [ms/100% activation]";
CM_ SG_ 89 HiBeamBrghtLeft_D_Rq "Brightness command to HighBeam";
CM_ SG_ 89 HiBeamFadeVRight_T_Rq "Theatre fading speed command to HighBeam. Time is defining [ms/100% activation]";
CM_ SG_ 89 HiBeamBrghtRight_D_Rq "Brightness command to HighBeam";
CM_ BO_ 117 "Message to transmit the status of the front right headlamp in regards to leveling, LED outage, LDM status";
CM_ SG_ 117 HlrHBFeedb_D_Stat "Feedback if lamp is actually executing a HB pending individual optical boundaries. (AHB Version before 3.0)";
CM_ SG_ 117 HlrHBSegFeedb_D_Stat "Feedback if lamp is actually executing a HB pending individual optical boundaries. (AHB Version after 3.0)";
CM_ SG_ 117 Hlr_Temp_Stat "Provide Headlamp Overtemperature Status.";
CM_ SG_ 117 Mdule1RightHl_side_Stat "Provide side detection status";
CM_ SG_ 117 Mdule1RightHl_Com_Stat "Provide physical CAN bus status. Trigger Physical CAN bus DTC";
CM_ SG_ 117 Mdule1Right_MPwr_B_Stat "Provide Main Power supply status. Triger Main Power Supply DTC.";
CM_ SG_ 117 Mdule1Right_LB_Pwr_B_Stat "Provide LB Power supply status.Triger LB Power Supply DTC";
CM_ SG_ 117 Hlr_SM_Stat "Provide SM unit status. Triger SM general electircal failure DTC";
CM_ SG_ 117 Hlr_SBL_Stat "Provide SBL unit status. Triger SBL general electircal failure DTC";
CM_ SG_ 117 Hlr_Pixel_Stat "Provide Pixel unit status. Triger Pixel general electircal failure DTC";
CM_ SG_ 117 Hlr_Fan_B_Stat "Provide fan status.Triger FAN DTC";
CM_ SG_ 117 Hlr_DRL_POS_Stat "Provide DRL_POS unit status. riger DRL general electircal failure DTC";
CM_ SG_ 117 Hlr_LvlMotor_Temp_Stat "Determing stepper temperature status";
CM_ SG_ 117 HeadLghtLvlRght_D_Stat "Command to start referencing run including leveling and beam shape changes. ";
CM_ SG_ 117 HeadLghtLvlRght_No_Stat "Command to move leveling. Given in half steps.";
CM_ SG_ 117 Mdule1RightFail_B_Stat "LDM Feedback of headlamp and LDM health status. This signal shall be used for DTC generation through HCM";
CM_ SG_ 117 Mdule1RightConfg_B_Stat "LDM Feedback of configuration state";
CM_ BO_ 116 "Message to transmit the status of the front left headlamp in regards to leveling, LED outage, LDM status";
CM_ SG_ 116 HllHBFeedb_D_Stat "Feedback if lamp is actually executing a HB pending individual optical boundaries. (AHB Version before 3.0)";
CM_ SG_ 116 HeadLghtLvlLeft_No_Stat "Command to move leveling. Given in half steps.";
CM_ SG_ 116 HllHBSegFeedb_D_Stat "Feedback if lamp is actually executing a HB pending individual optical boundaries. (AHB Version after 3.0)";
CM_ SG_ 116 Hll_Temp_Stat "Provide Headlamp Overtemperature Status.";
CM_ SG_ 116 Mdule1LeftHl_side_Stat "Provide side detection status";
CM_ SG_ 116 Mdule1LeftHl_Com_Stat "Provide physical CAN bus status. Trigger Physical CAN bus DTC";
CM_ SG_ 116 Mdule1Left_MPwr_B_Stat "Provide Main Power supply status. Triger Main Power Supply DTC.";
CM_ SG_ 116 Mdule1Left_LB_Pwr_B_Stat "Provide LB Power supply status.Triger LB Power Supply DTC";
CM_ SG_ 116 Hll_SM_Stat "Provide SM unit status. Triger SM general electircal failure DTC";
CM_ SG_ 116 Hll_SBL_Stat "Provide SBL unit status. Triger SBL general electircal failure DTC";
CM_ SG_ 116 Hll_Pixel_Stat "Provide Pixel unit status. Triger Pixel general electircal failure DTC";
CM_ SG_ 116 Hll_Fan_B_Stat "Provide fan status.Triger FAN DTC";
CM_ SG_ 116 Hll_DRL_POS_Stat "Provide DRL_POS unit status. riger DRL general electircal failure DTC";
CM_ SG_ 116 Hll_LvlMotor_Temp_Stat "Determing stepper motor temperature status";
CM_ SG_ 116 HeadLghtLvlLeft_D_Stat "Command to start referencing run including leveling and beam shape changes. ";
CM_ SG_ 116 Mdule1LeftFail_B_Stat "LDM Feedback of headlamp and LDM health status. This signal shall be used for DTC generation through HCM";
CM_ SG_ 116 Mdule1LeftConfg_B_Stat "LDM Feedback of configuration state";
CM_ BO_ 118 "Message for headlamp leveling target data and headlamp reference run for leveling, swiveling and light modes";
CM_ SG_ 118 HeadLghtLvlRghtRef_D_Rq "Command to start referencing run including leveling and beam shape changes. ";
CM_ SG_ 118 HeadLghtLvlLeftRef_D_Rq "Command to start referencing run including leveling and beam shape changes. ";
CM_ SG_ 118 HeadLghtLvlRight_No_Rq "Command to move leveling. Given in half  steps.";
CM_ SG_ 118 HeadLghtLvlLeft_No_Rq "Command to move leveling. Given in half steps.";
CM_ BO_ 85 "Vehicle operation modes for Microhybrid / StartStop low voltage behavior";
CM_ SG_ 85 HCMSleepyTime_B_Stat "Ignition status";
CM_ SG_ 85 Ignition_Status "Ignition status";
CM_ SG_ 85 PwPckTq_D_Stat "Required determining the powertrain start/ stop status preparing for battery low voltage state";
CM_ SG_ 85 ElPw_D_Stat "Required determining the powertrain start/ stop status preparing for battery low voltage state";
CM_ BO_ 98 "Low Beam Shape definition, Swiveling Target Angle and Tourist Mode request (Traffic Style)";
CM_ SG_ 98 Traffic_Style_Rq "Tourist mode. 
0x01 changes the vehicle default beam shape to the opposite. 
Default beam shape is dependant on the traffic side the vehicle has been licensed to";
CM_ SG_ 98 SwvlTrgtLeft_An_Rq "Dynamic bending light target angle command left headlamp";
CM_ SG_ 98 SwvlTrgtRight_An_Rq "Dynamic bending light target angle command right headlamp";
CM_ SG_ 98 LowBeamLightClassL_T_Rq "Command to transition speed of one Speed dependend light mode state to another . Does not change the SBL/ SSBL light sources.";
CM_ SG_ 98 LowBeamLightClassR_T_Rq "Command to transition speed of one Speed dependend light mode state to another . Does not change the SBL/ SSBL light sources.";
CM_ SG_ 98 LowBeamLightClassL_D_Rq "Command to change the Speed dependend light mode state. Does not change the SBL/ SSBL light sources.";
CM_ SG_ 98 LowBeamLightClassR_D_Rq "Command to change the Speed dependend light mode state. Does not change the SBL/ SSBL light sources.";
CM_ BO_ 113 "Message to control the SBL and SSBL on right headlamp";
CM_ SG_ 113 Slght5VRight_T_Rq "Supplementary light source (SSBL) rate of change of activation [ms to 100%]";
CM_ SG_ 113 Slght5BrghtRight_Pc_Rq "Supplementary light source (SSBL) rate of activation";
CM_ SG_ 113 Slght4VRight_T_Rq "Supplementary light source (SSBL) rate of change of activation [ms to 100%]";
CM_ SG_ 113 Slght4BrghtRight_Pc_Rq "Supplementary light source (SSBL) rate of activation";
CM_ SG_ 113 Slght3VRight_T_Rq "Supplementary light source (SSBL) rate of change of activation [ms to 100%]";
CM_ SG_ 113 Slght3BrghtRight_Pc_Rq "Supplementary light source (SSBL) rate of activation";
CM_ SG_ 113 Slght2VRight_T_Rq "Supplementary light source (SSBL) rate of change of activation [ms to 100%]";
CM_ SG_ 113 Slght2BrghtRight_Pc_Rq "Supplementary light source (SSBL) rate of activation";
CM_ SG_ 113 Slght1VRight_T_Rq "Supplementary light source (SSBL) rate of change of activation [ms to 100%]";
CM_ SG_ 113 Slght1BrghtRight_Pc_Rq "Supplementary light source (SSBL or SBL) rate of activation";
CM_ BO_ 112 "Message to control the SBL and SSBL on left headlamp";
CM_ SG_ 112 Slght5VLeft_T_Rq "Supplementary light source (SSBL) rate of change of activation [ms to 100%]";
CM_ SG_ 112 Slght5BrghtLeft_Pc_Rq "Supplementary light source (SSBL) rate of activation";
CM_ SG_ 112 Slght4VLeft_T_Rq "Supplementary light source (SSBL) rate of change of activation [ms to 100%]";
CM_ SG_ 112 Slght4BrghtLeft_Pc_Rq "Supplementary light source (SSBL) rate of activation";
CM_ SG_ 112 Slght3VLeft_T_Rq "Supplementary light source (SSBL) rate of change of activation [ms to 100%]";
CM_ SG_ 112 Slght3BrghtLeft_Pc_Rq "Supplementary light source (SSBL) rate of activation";
CM_ SG_ 112 Slght2VLeft_T_Rq "Supplementary light source (SSBL) rate of change of activation [ms to 100%]";
CM_ SG_ 112 Slght2BrghtLeft_Pc_Rq "Supplementary light source (SSBL) rate of activation";
CM_ SG_ 112 Slght1VLeft_T_Rq "Supplementary light source (SSBL) rate of change of activation [ms to 100%]";
CM_ SG_ 112 Slght1BrghtLeft_Pc_Rq "Supplementary light source (SSBL or SBL) rate of activation";
CM_ BO_ 97 "Message for right headlamp describing the spot for GFHB/ ADB feature";
CM_ SG_ 97 Hlrspot1_Rq "Spot request";
CM_ SG_ 97 Hlrspot1TrgtUp_An_Rq "Target angle of the spot given an imaginary rectangle from the current vehicle H-H line (horizon)";
CM_ SG_ 97 Hlrspot1TrgtDown_An_Rq "Target angle of the spot given an imaginary rectangle from the current vehicle H-H line (horizon)";
CM_ SG_ 97 Hlrspot1TrgtLeft_An_Rq "Target angle of the spot given an imaginary rectangle from the current vehicle H-H line (horizon)";
CM_ SG_ 97 Hlrspot1TrgtRght_An_Rq "Target angle of the spot given an imaginary rectangle from the current vehicle H-H line (horizon)";
CM_ SG_ 97 Hlrspot1V_T_Rq "Theatre fading speed command to HighBeamSpot. Time is defining [ms/0% activation]";
CM_ SG_ 97 Hlrspot1Brght_Pc_Rq "Brightness command to HighBeamSpot for right headlamp Spot";
BA_DEF_ BO_  "OvtpPushApplication" ENUM  "FALSE","TRUE";
BA_DEF_ BU_  "OvtpOperationMode" ENUM  "SERVER","CLIENT";
BA_DEF_ BU_  "OvtpEcuAddress" INT 0 1022;
BA_DEF_ SG_  "GenSigTimeoutTime_X_LDMFL1" INT 0 100000;
BA_DEF_ SG_  "GenSigTimeoutTime_X_LDMFR1" INT 0 100000;
BA_DEF_ SG_  "GenSigTimeoutTime_HCM_SUBNET" INT 0 100000;
BA_DEF_ BO_  "NetworkInitialization" ENUM  "No","Yes";
BA_DEF_ BO_  "EventRateOfChange" INT 10 10000;
BA_DEF_ BO_  "GenMsgStartDelayTime" INT 0 10000;
BA_DEF_ BO_  "GenMsgNrOfRepetition" INT 0 100;
BA_DEF_ BO_  "GenMsgDelayTime" INT 0 1000;
BA_DEF_ BO_  "GenMsgCycleTime" INT 0 100000;
BA_DEF_ BO_  "GenMsgSendType" ENUM  "FixedPeriodic","Event","EnabledPeriodic","NotUsed","NotUsed","EventPeriodic","NotUsed","NotUsed","NoMsgSendType";
BA_DEF_ SG_  "U_U611_U625_MY20_Phev_Tx" ENUM  "No","Yes";
BA_DEF_ SG_  "U_C519_MCA_MY22_Tx" ENUM  "No","Yes";
BA_DEF_ SG_  "U_U554_MCA_MY22_Tx" ENUM  "No","Yes";
BA_DEF_ SG_  "U_C519_MCA_MY22_Rx" ENUM  "No","Yes";
BA_DEF_ SG_  "U_U554_MCA_MY22_Rx" ENUM  "No","Yes";
BA_DEF_ SG_  "MetaData" ENUM  "No","Yes";
BA_DEF_ SG_  "ContentDependant" ENUM  "No","Yes";
BA_DEF_ SG_  "GenSigStartValue" INT 0 1000000000;
BA_DEF_ SG_  "UsedOnPgmDBC" ENUM  "No","Yes";
BA_DEF_ SG_  "GenSigSendType" ENUM  "Cyclic","OnWrite","vector_leerstring","OnChange","vector_leerstring","IfActive","vector_leerstring","NoSigSendType";
BA_DEF_ BO_  "DiagState" ENUM  "No","Yes";
BA_DEF_ BO_  "TpTxIndex" INT 0 536870911;
BA_DEF_ BO_  "DiagRequest" ENUM  "No","Yes";
BA_DEF_ BO_  "DiagResponse" ENUM  "No","Yes";
BA_DEF_ BO_  "GenMsgILSupport" ENUM  "No","Yes";
BA_DEF_ BU_  "Terminator" ENUM  "No","Yes";
BA_DEF_ BU_  "NodeWakeUpTime" INT 0 10000;
BA_DEF_ BU_  "NodeStartUpTime" INT 0 10000;
BA_DEF_ BU_  "NmAsrNodeIdentifier" HEX 128 255;
BA_DEF_ BU_  "PowerType" ENUM  "Switched","Latched","Sleep","vector_leerstring","vector_leerstring";
BA_DEF_ BU_  "DiagNode" ENUM  "GGDS","GDS","NONE";
BA_DEF_ BU_  "EOL_SB_Flash" ENUM  "GGDS","GDS","NONE","vector_leerstring";
BA_DEF_ BU_  "NmStationAddress" INT 0 255;
BA_DEF_ BU_  "ILUsed" ENUM  "No","Yes";
BA_DEF_ BU_  "NosPackage" ENUM  "None","I3_1","I3_2","1.0.1","RP","EuCD","Volcano","I3_3","FNOS_Autosar";
BA_DEF_ BU_  "PackageID" STRING ;
BA_DEF_  "VersionNumber" INT 0 10000;
BA_DEF_  "StarNetworkGwType" ENUM  "0=NotDefined","1=HS1","2=HS2","3=HS3","4=HS4","5=HS5","6=MS1","7=HS6","8=HS7","9=MS2";
BA_DEF_  "CMDB_Version" STRING ;
BA_DEF_  "NmType" STRING ;
BA_DEF_  "NetworkSpeed" ENUM  "500kBits/s","125kBit/s";
BA_DEF_  "NmAsrMessageCount" INT 128 128;
BA_DEF_  "NmAsrBaseAddress" HEX 1408 1408;
BA_DEF_  "DBName" STRING ;
BA_DEF_  "VersionDay" INT 1 31;
BA_DEF_  "Manufacturer" STRING ;
BA_DEF_  "VersionMonth" INT 1 12;
BA_DEF_  "VersionYear" INT 2000 3000;
BA_DEF_  "NmBaseAddress" HEX 1280 1280;
BA_DEF_  "NmMessageCount" INT 0 128;
BA_DEF_DEF_  "OvtpPushApplication" "FALSE";
BA_DEF_DEF_  "OvtpOperationMode" "SERVER";
BA_DEF_DEF_  "OvtpEcuAddress" 0;
BA_DEF_DEF_  "GenSigTimeoutTime_X_LDMFL1" 5000;
BA_DEF_DEF_  "GenSigTimeoutTime_X_LDMFR1" 5000;
BA_DEF_DEF_  "GenSigTimeoutTime_HCM_SUBNET" 5000;
BA_DEF_DEF_  "NetworkInitialization" "Yes";
BA_DEF_DEF_  "EventRateOfChange" 10000;
BA_DEF_DEF_  "GenMsgStartDelayTime" 0;
BA_DEF_DEF_  "GenMsgNrOfRepetition" 1;
BA_DEF_DEF_  "GenMsgDelayTime" 20;
BA_DEF_DEF_  "GenMsgCycleTime" 0;
BA_DEF_DEF_  "GenMsgSendType" "NoMsgSendType";
BA_DEF_DEF_  "U_U611_U625_MY20_Phev_Tx" "No";
BA_DEF_DEF_  "U_C519_MCA_MY22_Tx" "Yes";
BA_DEF_DEF_  "U_U554_MCA_MY22_Tx" "Yes";
BA_DEF_DEF_  "U_C519_MCA_MY22_Rx" "Yes";
BA_DEF_DEF_  "U_U554_MCA_MY22_Rx" "Yes";
BA_DEF_DEF_  "MetaData" "No";
BA_DEF_DEF_  "ContentDependant" "No";
BA_DEF_DEF_  "GenSigStartValue" 0;
BA_DEF_DEF_  "UsedOnPgmDBC" "Yes";
BA_DEF_DEF_  "GenSigSendType" "NoSigSendType";
BA_DEF_DEF_  "DiagState" "No";
BA_DEF_DEF_  "TpTxIndex" 0;
BA_DEF_DEF_  "DiagRequest" "No";
BA_DEF_DEF_  "DiagResponse" "No";
BA_DEF_DEF_  "GenMsgILSupport" "Yes";
BA_DEF_DEF_  "Terminator" "No";
BA_DEF_DEF_  "NodeWakeUpTime" 10;
BA_DEF_DEF_  "NodeStartUpTime" 250;
BA_DEF_DEF_  "NmAsrNodeIdentifier" 128;
BA_DEF_DEF_  "PowerType" "Switched";
BA_DEF_DEF_  "DiagNode" "GGDS";
BA_DEF_DEF_  "EOL_SB_Flash" "GGDS";
BA_DEF_DEF_  "NmStationAddress" 0;
BA_DEF_DEF_  "ILUsed" "Yes";
BA_DEF_DEF_  "NosPackage" "I3_3";
BA_DEF_DEF_  "PackageID" "08.05.00.00.71.xx.xx.rr.00.00";
BA_DEF_DEF_  "VersionNumber" 1;
BA_DEF_DEF_  "StarNetworkGwType" "0=NotDefined";
BA_DEF_DEF_  "CMDB_Version" "v11.01";
BA_DEF_DEF_  "NmType" "Ford-OSEK";
BA_DEF_DEF_  "NetworkSpeed" "500kBits/s";
BA_DEF_DEF_  "NmAsrMessageCount" 128;
BA_DEF_DEF_  "NmAsrBaseAddress" 1408;
BA_DEF_DEF_  "DBName" "";
BA_DEF_DEF_  "VersionDay" 1;
BA_DEF_DEF_  "Manufacturer" "Ford";
BA_DEF_DEF_  "VersionMonth" 1;
BA_DEF_DEF_  "VersionYear" 2011;
BA_DEF_DEF_  "NmBaseAddress" 1280;
BA_DEF_DEF_  "NmMessageCount" 128;
BA_ "VersionNumber" 10;
BA_ "CMDB_Version" "FNV2_v20.05";
BA_ "VersionDay" 19;
BA_ "VersionMonth" 2;
BA_ "VersionYear" 2021;
BA_ "DBName" "LightingBus";
BA_ "NmStationAddress" BU_ CSDB 54;
BA_ "NmStationAddress" BU_ CSDA 53;
BA_ "OvtpEcuAddress" BU_ HCM 113;
BA_ "OvtpOperationMode" BU_ HCM 1;
BA_ "NmStationAddress" BU_ HCM 28;
BA_ "NodeStartUpTime" BU_ HCM 105;
BA_ "OvtpEcuAddress" BU_ LDCMA 79;
BA_ "Terminator" BU_ LDCMA 1;
BA_ "NmStationAddress" BU_ LDCMA 79;
BA_ "NodeStartUpTime" BU_ LDCMA 200;
BA_ "OvtpEcuAddress" BU_ LDCMB 78;
BA_ "Terminator" BU_ LDCMB 1;
BA_ "NmStationAddress" BU_ LDCMB 78;
BA_ "NodeStartUpTime" BU_ LDCMB 200;
BA_ "GenMsgCycleTime" BO_ 784 100;
BA_ "GenMsgSendType" BO_ 784 5;
BA_ "GenMsgCycleTime" BO_ 768 100;
BA_ "GenMsgSendType" BO_ 768 5;
BA_ "TpTxIndex" BO_ 2612224078 464740430;
BA_ "GenMsgSendType" BO_ 2612224078 1;
BA_ "OvtpPushApplication" BO_ 2612224078 1;
BA_ "TpTxIndex" BO_ 2612082904 464599256;
BA_ "GenMsgSendType" BO_ 2612082904 1;
BA_ "OvtpPushApplication" BO_ 2612082904 1;
BA_ "TpTxIndex" BO_ 2611175502 463691854;
BA_ "GenMsgSendType" BO_ 2611175502 1;
BA_ "GenMsgDelayTime" BO_ 2611175502 0;
BA_ "TpTxIndex" BO_ 2611034328 463550680;
BA_ "GenMsgSendType" BO_ 2611034328 1;
BA_ "GenMsgDelayTime" BO_ 2611034328 0;
BA_ "TpTxIndex" BO_ 2610126926 462643278;
BA_ "GenMsgSendType" BO_ 2610126926 1;
BA_ "TpTxIndex" BO_ 2609985752 462502104;
BA_ "GenMsgSendType" BO_ 2609985752 1;
BA_ "GenMsgDelayTime" BO_ 2609985752 0;
BA_ "OvtpPushApplication" BO_ 2612224079 1;
BA_ "DiagResponse" BO_ 2612224079 1;
BA_ "TpTxIndex" BO_ 2612224079 464740431;
BA_ "GenMsgSendType" BO_ 2612224079 1;
BA_ "DiagRequest" BO_ 1798 1;
BA_ "GenMsgSendType" BO_ 1798 1;
BA_ "GenMsgDelayTime" BO_ 1798 0;
BA_ "NetworkInitialization" BO_ 1798 0;
BA_ "DiagResponse" BO_ 1806 1;
BA_ "GenMsgSendType" BO_ 1806 1;
BA_ "GenMsgDelayTime" BO_ 1806 0;
BA_ "NetworkInitialization" BO_ 1806 0;
BA_ "GenMsgStartDelayTime" BO_ 800 100;
BA_ "GenMsgCycleTime" BO_ 800 100;
BA_ "GenMsgSendType" BO_ 800 5;
BA_ "GenMsgDelayTime" BO_ 800 0;
BA_ "GenMsgCycleTime" BO_ 121 10;
BA_ "GenMsgSendType" BO_ 121 0;
BA_ "GenMsgDelayTime" BO_ 121 0;
BA_ "GenMsgCycleTime" BO_ 120 10;
BA_ "GenMsgSendType" BO_ 120 0;
BA_ "GenMsgDelayTime" BO_ 120 0;
BA_ "GenMsgCycleTime" BO_ 119 10;
BA_ "GenMsgSendType" BO_ 119 0;
BA_ "GenMsgDelayTime" BO_ 119 0;
BA_ "NetworkInitialization" BO_ 1805 0;
BA_ "GenMsgDelayTime" BO_ 1805 0;
BA_ "GenMsgSendType" BO_ 1805 1;
BA_ "DiagResponse" BO_ 1805 1;
BA_ "NetworkInitialization" BO_ 1797 0;
BA_ "GenMsgDelayTime" BO_ 1797 0;
BA_ "GenMsgSendType" BO_ 1797 1;
BA_ "DiagRequest" BO_ 1797 1;
BA_ "NetworkInitialization" BO_ 1796 0;
BA_ "GenMsgDelayTime" BO_ 1796 0;
BA_ "GenMsgSendType" BO_ 1796 1;
BA_ "DiagRequest" BO_ 1796 1;
BA_ "NetworkInitialization" BO_ 1804 0;
BA_ "GenMsgDelayTime" BO_ 1804 0;
BA_ "GenMsgSendType" BO_ 1804 1;
BA_ "DiagResponse" BO_ 1804 1;
BA_ "TpTxIndex" BO_ 2611035352 463551704;
BA_ "GenMsgDelayTime" BO_ 2611035352 0;
BA_ "GenMsgSendType" BO_ 2611035352 1;
BA_ "OvtpPushApplication" BO_ 2612083928 1;
BA_ "TpTxIndex" BO_ 2612083928 464600280;
BA_ "GenMsgSendType" BO_ 2612083928 1;
BA_ "OvtpPushApplication" BO_ 2611175503 1;
BA_ "TpTxIndex" BO_ 2611175503 463691855;
BA_ "GenMsgSendType" BO_ 2611175503 1;
BA_ "GenMsgDelayTime" BO_ 2611175503 0;
BA_ "TpTxIndex" BO_ 2612002008 464518360;
BA_ "GenMsgSendType" BO_ 2612002008 1;
BA_ "GenMsgDelayTime" BO_ 2612002008 0;
BA_ "TpTxIndex" BO_ 2610126927 462643279;
BA_ "GenMsgSendType" BO_ 2610126927 1;
BA_ "TpTxIndex" BO_ 2609986776 462503128;
BA_ "GenMsgDelayTime" BO_ 2609986776 0;
BA_ "GenMsgSendType" BO_ 2609986776 1;
BA_ "TpTxIndex" BO_ 2610953432 463469784;
BA_ "GenMsgDelayTime" BO_ 2610953432 0;
BA_ "GenMsgSendType" BO_ 2610953432 1;
BA_ "GenMsgStartDelayTime" BO_ 80 100;
BA_ "GenMsgCycleTime" BO_ 80 500;
BA_ "GenMsgSendType" BO_ 80 5;
BA_ "GenMsgDelayTime" BO_ 80 0;
BA_ "GenMsgSendType" BO_ 103 0;
BA_ "GenMsgCycleTime" BO_ 103 20;
BA_ "GenMsgDelayTime" BO_ 103 0;
BA_ "GenMsgSendType" BO_ 102 0;
BA_ "GenMsgCycleTime" BO_ 102 20;
BA_ "GenMsgDelayTime" BO_ 102 0;
BA_ "GenMsgSendType" BO_ 101 0;
BA_ "GenMsgCycleTime" BO_ 101 20;
BA_ "GenMsgDelayTime" BO_ 101 0;
BA_ "GenMsgCycleTime" BO_ 100 20;
BA_ "GenMsgSendType" BO_ 100 0;
BA_ "GenMsgDelayTime" BO_ 100 0;
BA_ "DiagState" BO_ 2015 1;
BA_ "NetworkInitialization" BO_ 2015 0;
BA_ "GenMsgDelayTime" BO_ 2015 0;
BA_ "GenMsgSendType" BO_ 2015 1;
BA_ "GenMsgILSupport" BO_ 2015 0;
BA_ "NetworkInitialization" BO_ 1791 0;
BA_ "GenMsgDelayTime" BO_ 1791 0;
BA_ "GenMsgSendType" BO_ 1791 1;
BA_ "DiagResponse" BO_ 1791 1;
BA_ "NetworkInitialization" BO_ 1790 0;
BA_ "GenMsgDelayTime" BO_ 1790 0;
BA_ "GenMsgSendType" BO_ 1790 1;
BA_ "DiagResponse" BO_ 1790 1;
BA_ "NetworkInitialization" BO_ 1783 0;
BA_ "GenMsgDelayTime" BO_ 1783 0;
BA_ "GenMsgSendType" BO_ 1783 1;
BA_ "DiagRequest" BO_ 1783 1;
BA_ "NetworkInitialization" BO_ 1782 0;
BA_ "GenMsgDelayTime" BO_ 1782 0;
BA_ "GenMsgSendType" BO_ 1782 1;
BA_ "DiagRequest" BO_ 1782 1;
BA_ "GenMsgCycleTime" BO_ 96 20;
BA_ "GenMsgSendType" BO_ 96 0;
BA_ "GenMsgDelayTime" BO_ 96 0;
BA_ "GenMsgSendType" BO_ 89 0;
BA_ "GenMsgCycleTime" BO_ 89 20;
BA_ "GenMsgDelayTime" BO_ 89 0;
BA_ "GenMsgSendType" BO_ 117 0;
BA_ "GenMsgCycleTime" BO_ 117 100;
BA_ "GenMsgDelayTime" BO_ 117 0;
BA_ "GenMsgSendType" BO_ 116 0;
BA_ "GenMsgCycleTime" BO_ 116 100;
BA_ "GenMsgDelayTime" BO_ 116 0;
BA_ "GenMsgSendType" BO_ 118 0;
BA_ "GenMsgCycleTime" BO_ 118 30;
BA_ "GenMsgDelayTime" BO_ 118 0;
BA_ "GenMsgSendType" BO_ 85 0;
BA_ "GenMsgCycleTime" BO_ 85 10;
BA_ "GenMsgDelayTime" BO_ 85 0;
BA_ "GenMsgCycleTime" BO_ 98 30;
BA_ "GenMsgSendType" BO_ 98 0;
BA_ "GenMsgDelayTime" BO_ 98 0;
BA_ "GenMsgCycleTime" BO_ 113 30;
BA_ "GenMsgSendType" BO_ 113 0;
BA_ "GenMsgDelayTime" BO_ 113 0;
BA_ "GenMsgCycleTime" BO_ 112 30;
BA_ "GenMsgSendType" BO_ 112 0;
BA_ "GenMsgDelayTime" BO_ 112 0;
BA_ "GenMsgCycleTime" BO_ 97 20;
BA_ "GenMsgSendType" BO_ 97 0;
BA_ "GenMsgDelayTime" BO_ 97 0;
BA_ "U_U611_U625_MY20_Phev_Tx" SG_ 3221225472 HeadLghtLvlRghtRef_D_Rq 1;
BA_ "U_U611_U625_MY20_Phev_Tx" SG_ 3221225472 HeadLghtLvlLeftRef_D_Rq 1;
BA_ "U_U611_U625_MY20_Phev_Tx" SG_ 3221225472 HeadLghtLvlRight_No_Rq 1;
BA_ "U_U611_U625_MY20_Phev_Tx" SG_ 3221225472 HeadLghtLvlLeft_No_Rq 1;
BA_ "U_U611_U625_MY20_Phev_Tx" SG_ 3221225472 HeadLghtDblRght_No_Stat 1;
BA_ "U_U611_U625_MY20_Phev_Tx" SG_ 3221225472 HeadLghtDblLeft_No_Stat 1;
BA_ "U_U611_U625_MY20_Phev_Tx" SG_ 3221225472 HeadLghtDblRight_No_Rq 1;
BA_ "U_U611_U625_MY20_Phev_Tx" SG_ 3221225472 HeadLghtDblLeft_No_Rq 1;
BA_ "U_U611_U625_MY20_Phev_Tx" SG_ 3221225472 Hlr_Foregrd_Stat 1;
BA_ "U_U611_U625_MY20_Phev_Tx" SG_ 3221225472 Hll_Foregrd_Stat 1;
BA_ "GenSigSendType" SG_ 3221225472 Tracer_Turn_Actv_Rq 3;
BA_ "GenSigSendType" SG_ 3221225472 LowBeam_Stat 3;
BA_ "GenSigSendType" SG_ 3221225472 Turn_Actv_Rf_Rq 3;
BA_ "GenSigSendType" SG_ 3221225472 Turn_Actv_Lf_Rq 3;
BA_ "GenSigStartValue" SG_ 3221225472 HeadLampLoFrOut_B_Stat 1;
BA_ "U_U611_U625_MY20_Phev_Tx" SG_ 3221225472 TurnLampFrOut_B_Stat 1;
BA_ "GenSigStartValue" SG_ 3221225472 HeadLampLoFlOut_B_Stat 1;
BA_ "U_U611_U625_MY20_Phev_Tx" SG_ 3221225472 TurnLampFlOut_B_Stat 1;
BA_ "U_U611_U625_MY20_Phev_Tx" SG_ 784 TurnLampFrOut_B_Stat 1;
BA_ "GenSigSendType" SG_ 784 TurnLampFrOut_B_Stat 3;
BA_ "GenSigStartValue" SG_ 784 HeadLampLoFrOut_B_Stat 1;
BA_ "GenSigSendType" SG_ 784 HeadLampLoFrOut_B_Stat 3;
BA_ "U_U554_MCA_MY22_Rx" SG_ 784 CanMsg_No_Crc 0;
BA_ "U_C519_MCA_MY22_Rx" SG_ 784 CanMsg_No_Crc 0;
BA_ "U_U554_MCA_MY22_Tx" SG_ 784 CanMsg_No_Crc 0;
BA_ "U_C519_MCA_MY22_Tx" SG_ 784 CanMsg_No_Crc 0;
BA_ "MetaData" SG_ 784 CanMsg_No_Crc 1;
BA_ "GenSigSendType" SG_ 784 CanMsg_No_Crc 3;
BA_ "U_U554_MCA_MY22_Rx" SG_ 784 CanMsg_No_Cnt 0;
BA_ "U_C519_MCA_MY22_Rx" SG_ 784 CanMsg_No_Cnt 0;
BA_ "U_U554_MCA_MY22_Tx" SG_ 784 CanMsg_No_Cnt 0;
BA_ "U_C519_MCA_MY22_Tx" SG_ 784 CanMsg_No_Cnt 0;
BA_ "ContentDependant" SG_ 784 CanMsg_No_Cnt 1;
BA_ "MetaData" SG_ 784 CanMsg_No_Cnt 1;
BA_ "GenSigSendType" SG_ 784 CanMsg_No_Cnt 3;
BA_ "U_U611_U625_MY20_Phev_Tx" SG_ 768 TurnLampFlOut_B_Stat 1;
BA_ "GenSigSendType" SG_ 768 TurnLampFlOut_B_Stat 3;
BA_ "GenSigStartValue" SG_ 768 HeadLampLoFlOut_B_Stat 1;
BA_ "GenSigSendType" SG_ 768 HeadLampLoFlOut_B_Stat 3;
BA_ "U_U554_MCA_MY22_Rx" SG_ 768 CanMsg_No_Crc 0;
BA_ "U_U554_MCA_MY22_Tx" SG_ 768 CanMsg_No_Crc 0;
BA_ "U_C519_MCA_MY22_Rx" SG_ 768 CanMsg_No_Crc 0;
BA_ "U_C519_MCA_MY22_Tx" SG_ 768 CanMsg_No_Crc 0;
BA_ "MetaData" SG_ 768 CanMsg_No_Crc 1;
BA_ "GenSigSendType" SG_ 768 CanMsg_No_Crc 3;
BA_ "U_U554_MCA_MY22_Rx" SG_ 768 CanMsg_No_Cnt 0;
BA_ "U_C519_MCA_MY22_Rx" SG_ 768 CanMsg_No_Cnt 0;
BA_ "U_U554_MCA_MY22_Tx" SG_ 768 CanMsg_No_Cnt 0;
BA_ "U_C519_MCA_MY22_Tx" SG_ 768 CanMsg_No_Cnt 0;
BA_ "ContentDependant" SG_ 768 CanMsg_No_Cnt 1;
BA_ "MetaData" SG_ 768 CanMsg_No_Cnt 1;
BA_ "GenSigSendType" SG_ 768 CanMsg_No_Cnt 3;
BA_ "GenSigSendType" SG_ 1553 XCP_TSTRtoLDCMB 3;
BA_ "GenSigSendType" SG_ 1552 XCP_TSTRtoLDCMA 3;
BA_ "GenSigSendType" SG_ 1537 XCP_LDCMBtoTSTR 3;
BA_ "GenSigSendType" SG_ 1536 XCP_LDCMAtoTSTR 3;
BA_ "GenSigSendType" SG_ 2612224078 PARSEDPushLDCMBtoGWM_ECG 3;
BA_ "GenSigTimeoutTime_HCM_SUBNET" SG_ 2612224078 PARSEDPushLDCMBtoGWM_ECG 0;
BA_ "GenSigTimeoutTime_X_LDMFR1" SG_ 2612224078 PARSEDPushLDCMBtoGWM_ECG 0;
BA_ "GenSigTimeoutTime_X_LDMFL1" SG_ 2612224078 PARSEDPushLDCMBtoGWM_ECG 0;
BA_ "GenSigSendType" SG_ 2612082904 PARSEDPushFcGWM_ECGtoLDCMB 3;
BA_ "GenSigTimeoutTime_HCM_SUBNET" SG_ 2612082904 PARSEDPushFcGWM_ECGtoLDCMB 0;
BA_ "GenSigTimeoutTime_X_LDMFR1" SG_ 2612082904 PARSEDPushFcGWM_ECGtoLDCMB 0;
BA_ "GenSigTimeoutTime_X_LDMFL1" SG_ 2612082904 PARSEDPushFcGWM_ECGtoLDCMB 0;
BA_ "GenSigSendType" SG_ 2611175502 PARSEDPhysLDCMBtoGWM_ECG 3;
BA_ "GenSigTimeoutTime_HCM_SUBNET" SG_ 2611175502 PARSEDPhysLDCMBtoGWM_ECG 0;
BA_ "GenSigTimeoutTime_X_LDMFR1" SG_ 2611175502 PARSEDPhysLDCMBtoGWM_ECG 0;
BA_ "GenSigTimeoutTime_X_LDMFL1" SG_ 2611175502 PARSEDPhysLDCMBtoGWM_ECG 0;
BA_ "GenSigTimeoutTime_X_LDMFL1" SG_ 2611034328 PARSEDPhysGWM_ECGtoLDCMB 0;
BA_ "GenSigTimeoutTime_X_LDMFR1" SG_ 2611034328 PARSEDPhysGWM_ECGtoLDCMB 0;
BA_ "GenSigTimeoutTime_HCM_SUBNET" SG_ 2611034328 PARSEDPhysGWM_ECGtoLDCMB 0;
BA_ "GenSigSendType" SG_ 2611034328 PARSEDPhysGWM_ECGtoLDCMB 3;
BA_ "GenSigTimeoutTime_X_LDMFL1" SG_ 2610126926 OTAPhysLDCMBtoGWM_ECG 0;
BA_ "GenSigTimeoutTime_X_LDMFR1" SG_ 2610126926 OTAPhysLDCMBtoGWM_ECG 0;
BA_ "GenSigTimeoutTime_HCM_SUBNET" SG_ 2610126926 OTAPhysLDCMBtoGWM_ECG 0;
BA_ "GenSigSendType" SG_ 2610126926 OTAPhysLDCMBtoGWM_ECG 3;
BA_ "GenSigTimeoutTime_X_LDMFL1" SG_ 2609985752 OTAPhysGWM_ECGtoLDCMB 0;
BA_ "GenSigTimeoutTime_X_LDMFR1" SG_ 2609985752 OTAPhysGWM_ECGtoLDCMB 0;
BA_ "GenSigTimeoutTime_HCM_SUBNET" SG_ 2609985752 OTAPhysGWM_ECGtoLDCMB 0;
BA_ "GenSigSendType" SG_ 2609985752 OTAPhysGWM_ECGtoLDCMB 3;
BA_ "GenSigSendType" SG_ 2612224079 PARSEDPushLDCMAtoGWM_ECG 3;
BA_ "GenSigTimeoutTime_HCM_SUBNET" SG_ 2612224079 PARSEDPushLDCMAtoGWM_ECG 0;
BA_ "GenSigTimeoutTime_X_LDMFR1" SG_ 2612224079 PARSEDPushLDCMAtoGWM_ECG 0;
BA_ "GenSigTimeoutTime_X_LDMFL1" SG_ 2612224079 PARSEDPushLDCMAtoGWM_ECG 0;
BA_ "GenSigSendType" SG_ 1798 TesterPhysicalReqDev 3;
BA_ "GenSigSendType" SG_ 1806 TesterPhysicalResDev 3;
BA_ "U_U554_MCA_MY22_Rx" SG_ 800 CanMsg_No_Crc 0;
BA_ "U_C519_MCA_MY22_Rx" SG_ 800 CanMsg_No_Crc 0;
BA_ "U_U554_MCA_MY22_Tx" SG_ 800 CanMsg_No_Crc 0;
BA_ "U_C519_MCA_MY22_Tx" SG_ 800 CanMsg_No_Crc 0;
BA_ "MetaData" SG_ 800 CanMsg_No_Crc 1;
BA_ "GenSigSendType" SG_ 800 CanMsg_No_Crc 3;
BA_ "U_U554_MCA_MY22_Rx" SG_ 800 CanMsg_No_Cnt 0;
BA_ "U_C519_MCA_MY22_Rx" SG_ 800 CanMsg_No_Cnt 0;
BA_ "U_U554_MCA_MY22_Tx" SG_ 800 CanMsg_No_Cnt 0;
BA_ "U_C519_MCA_MY22_Tx" SG_ 800 CanMsg_No_Cnt 0;
BA_ "ContentDependant" SG_ 800 CanMsg_No_Cnt 1;
BA_ "MetaData" SG_ 800 CanMsg_No_Cnt 1;
BA_ "GenSigSendType" SG_ 800 CanMsg_No_Cnt 3;
BA_ "GenSigSendType" SG_ 800 TurnLghtRight_D_Rq 3;
BA_ "GenSigSendType" SG_ 800 TurnLghtLeft_D_Rq 3;
BA_ "GenSigStartValue" SG_ 800 HeadLampLoFrOn_B_Stat 1;
BA_ "GenSigSendType" SG_ 800 HeadLampLoFrOn_B_Stat 3;
BA_ "GenSigStartValue" SG_ 800 HeadLampLoFlOn_B_Stat 1;
BA_ "GenSigSendType" SG_ 800 HeadLampLoFlOn_B_Stat 3;
BA_ "U_U611_U625_MY20_Phev_Tx" SG_ 121 DblMtrRight_Motion_B_Stat 1;
BA_ "GenSigStartValue" SG_ 121 SwvlTrgtRight_An_D_Stat 875;
BA_ "U_U611_U625_MY20_Phev_Tx" SG_ 121 SwvlTrgtRight_An_D_Stat 1;
BA_ "U_U611_U625_MY20_Phev_Tx" SG_ 121 HeadLghtDblRght_D_Stat 1;
BA_ "U_U611_U625_MY20_Phev_Tx" SG_ 120 DblMtrLeft_Motion_B_Stat 1;
BA_ "GenSigStartValue" SG_ 120 SwvlTrgtLeft_An_D_Stat 875;
BA_ "U_U611_U625_MY20_Phev_Tx" SG_ 120 SwvlTrgtLeft_An_D_Stat 1;
BA_ "U_U611_U625_MY20_Phev_Tx" SG_ 120 HeadLghtDbllLeft_D_Stat 1;
BA_ "U_U611_U625_MY20_Phev_Tx" SG_ 119 HeadLghtDblRghtRef_D_Rq 1;
BA_ "U_U611_U625_MY20_Phev_Tx" SG_ 119 HeadLghtDblLeftRef_D_Rq 1;
BA_ "U_U611_U625_MY20_Phev_Tx" SG_ 119 MtrSwvlTrgtRight_An_Rq 1;
BA_ "GenSigStartValue" SG_ 119 MtrSwvlTrgtRight_An_Rq 875;
BA_ "U_U611_U625_MY20_Phev_Tx" SG_ 119 MtrSwvlTrgtLeft_An_Rq 1;
BA_ "GenSigStartValue" SG_ 119 MtrSwvlTrgtLeft_An_Rq 875;
BA_ "GenSigSendType" SG_ 1805 TesterPhysicalResCDSB 3;
BA_ "GenSigSendType" SG_ 1797 TesterPhysicalReqCDSB 3;
BA_ "GenSigSendType" SG_ 1796 TesterPhysicalReqCDSA 3;
BA_ "GenSigSendType" SG_ 1804 TesterPhysicalResCDSA 3;
BA_ "GenSigTimeoutTime_X_LDMFL1" SG_ 2611035352 PARSEDPhysGWM_ECGtoLDCMA 0;
BA_ "GenSigTimeoutTime_X_LDMFR1" SG_ 2611035352 PARSEDPhysGWM_ECGtoLDCMA 0;
BA_ "GenSigTimeoutTime_HCM_SUBNET" SG_ 2611035352 PARSEDPhysGWM_ECGtoLDCMA 0;
BA_ "GenSigSendType" SG_ 2611035352 PARSEDPhysGWM_ECGtoLDCMA 3;
BA_ "GenSigSendType" SG_ 2612083928 PARSEDPushFcGWM_ECGtoLDCMA 3;
BA_ "GenSigTimeoutTime_HCM_SUBNET" SG_ 2612083928 PARSEDPushFcGWM_ECGtoLDCMA 0;
BA_ "GenSigTimeoutTime_X_LDMFR1" SG_ 2612083928 PARSEDPushFcGWM_ECGtoLDCMA 0;
BA_ "GenSigTimeoutTime_X_LDMFL1" SG_ 2612083928 PARSEDPushFcGWM_ECGtoLDCMA 0;
BA_ "GenSigSendType" SG_ 2611175503 PARSEDPhysLDCMAtoGWM_ECG 3;
BA_ "GenSigTimeoutTime_HCM_SUBNET" SG_ 2611175503 PARSEDPhysLDCMAtoGWM_ECG 0;
BA_ "GenSigTimeoutTime_X_LDMFR1" SG_ 2611175503 PARSEDPhysLDCMAtoGWM_ECG 0;
BA_ "GenSigTimeoutTime_X_LDMFL1" SG_ 2611175503 PARSEDPhysLDCMAtoGWM_ECG 0;
BA_ "GenSigSendType" SG_ 2612002008 PARSEDFuncGWM_ECG 3;
BA_ "GenSigTimeoutTime_HCM_SUBNET" SG_ 2612002008 PARSEDFuncGWM_ECG 0;
BA_ "GenSigTimeoutTime_X_LDMFR1" SG_ 2612002008 PARSEDFuncGWM_ECG 0;
BA_ "GenSigTimeoutTime_X_LDMFL1" SG_ 2612002008 PARSEDFuncGWM_ECG 0;
BA_ "GenSigTimeoutTime_X_LDMFL1" SG_ 2610126927 OTAPhysLDCMAtoGWM_ECG 0;
BA_ "GenSigTimeoutTime_X_LDMFR1" SG_ 2610126927 OTAPhysLDCMAtoGWM_ECG 0;
BA_ "GenSigTimeoutTime_HCM_SUBNET" SG_ 2610126927 OTAPhysLDCMAtoGWM_ECG 0;
BA_ "GenSigSendType" SG_ 2610126927 OTAPhysLDCMAtoGWM_ECG 3;
BA_ "GenSigTimeoutTime_X_LDMFL1" SG_ 2609986776 OTAPhysGWM_ECGtoLDCMA 0;
BA_ "GenSigTimeoutTime_X_LDMFR1" SG_ 2609986776 OTAPhysGWM_ECGtoLDCMA 0;
BA_ "GenSigTimeoutTime_HCM_SUBNET" SG_ 2609986776 OTAPhysGWM_ECGtoLDCMA 0;
BA_ "GenSigSendType" SG_ 2609986776 OTAPhysGWM_ECGtoLDCMA 3;
BA_ "GenSigTimeoutTime_X_LDMFL1" SG_ 2610953432 OTAFuncGWM_ECG 0;
BA_ "GenSigTimeoutTime_X_LDMFR1" SG_ 2610953432 OTAFuncGWM_ECG 0;
BA_ "GenSigTimeoutTime_HCM_SUBNET" SG_ 2610953432 OTAFuncGWM_ECG 0;
BA_ "GenSigSendType" SG_ 2610953432 OTAFuncGWM_ECG 3;
BA_ "GenSigSendType" SG_ 80 DrlPos4_Actv_Rf_Rq 3;
BA_ "GenSigSendType" SG_ 80 DrlPos4_Actv_Lf_Rq 3;
BA_ "GenSigSendType" SG_ 80 DrlPos3_Actv_Rf_Rq 3;
BA_ "GenSigSendType" SG_ 80 DrlPos3_Actv_Lf_Rq 3;
BA_ "GenSigStartValue" SG_ 80 HeadLghtSwtch_D_Stat 2;
BA_ "GenSigSendType" SG_ 80 HeadLghtSwtch_D_Stat 3;
BA_ "U_U611_U625_MY20_Phev_Tx" SG_ 80 ExtLghtFront_D_RqBody 1;
BA_ "GenSigSendType" SG_ 80 ExtLghtFront_D_RqBody 3;
BA_ "GenSigSendType" SG_ 80 Front_Fog_Actv_Rq 3;
BA_ "GenSigSendType" SG_ 80 WfSubstate_D_Stat 3;
BA_ "GenSigSendType" SG_ 80 WfSuperstate_D_Stat 3;
BA_ "GenSigSendType" SG_ 80 Drl_Pos_Actv_Fade_Rf_Rq 3;
BA_ "GenSigSendType" SG_ 80 SideMarker_Actv_Rq 3;
BA_ "GenSigSendType" SG_ 80 Drl_Pos_Actv_Fade_Lf_Rq 3;
BA_ "GenSigSendType" SG_ 80 DrlPos2_Actv_Rf_Rq 3;
BA_ "GenSigSendType" SG_ 80 DrlPos1_Actv_Rf_Rq 3;
BA_ "GenSigSendType" SG_ 80 DrlPos2_Actv_Lf_Rq 3;
BA_ "GenSigSendType" SG_ 80 DrlPos1_Actv_Lf_Rq 3;
BA_ "U_C519_MCA_MY22_Rx" SG_ 103 Hlrspot3TrgtUp_An_Rq 0;
BA_ "U_C519_MCA_MY22_Tx" SG_ 103 Hlrspot3TrgtUp_An_Rq 0;
BA_ "GenSigStartValue" SG_ 103 Hlrspot3TrgtUp_An_Rq 875;
BA_ "U_U611_U625_MY20_Phev_Tx" SG_ 103 Hlrspot3TrgtUp_An_Rq 1;
BA_ "U_C519_MCA_MY22_Rx" SG_ 103 Hlrspot3TrgtDown_An_Rq 0;
BA_ "U_C519_MCA_MY22_Tx" SG_ 103 Hlrspot3TrgtDown_An_Rq 0;
BA_ "GenSigStartValue" SG_ 103 Hlrspot3TrgtDown_An_Rq 875;
BA_ "U_U611_U625_MY20_Phev_Tx" SG_ 103 Hlrspot3TrgtDown_An_Rq 1;
BA_ "U_C519_MCA_MY22_Rx" SG_ 103 Hlrspot3TrgtRght_An_Rq 0;
BA_ "U_C519_MCA_MY22_Tx" SG_ 103 Hlrspot3TrgtRght_An_Rq 0;
BA_ "GenSigStartValue" SG_ 103 Hlrspot3TrgtRght_An_Rq 875;
BA_ "U_U611_U625_MY20_Phev_Tx" SG_ 103 Hlrspot3TrgtRght_An_Rq 1;
BA_ "U_C519_MCA_MY22_Rx" SG_ 103 Hlrspot3TrgtLeft_An_Rq 0;
BA_ "U_C519_MCA_MY22_Tx" SG_ 103 Hlrspot3TrgtLeft_An_Rq 0;
BA_ "GenSigStartValue" SG_ 103 Hlrspot3TrgtLeft_An_Rq 875;
BA_ "U_U611_U625_MY20_Phev_Tx" SG_ 103 Hlrspot3TrgtLeft_An_Rq 1;
BA_ "U_C519_MCA_MY22_Rx" SG_ 103 Hlrspot3V_T_Rq 0;
BA_ "U_C519_MCA_MY22_Tx" SG_ 103 Hlrspot3V_T_Rq 0;
BA_ "U_U611_U625_MY20_Phev_Tx" SG_ 103 Hlrspot3V_T_Rq 1;
BA_ "U_C519_MCA_MY22_Rx" SG_ 103 Hlrspot3Brght_Pc_Rq 0;
BA_ "U_C519_MCA_MY22_Tx" SG_ 103 Hlrspot3Brght_Pc_Rq 0;
BA_ "U_U611_U625_MY20_Phev_Tx" SG_ 103 Hlrspot3Brght_Pc_Rq 1;
BA_ "U_C519_MCA_MY22_Rx" SG_ 103 Hlrspot3_Rq 0;
BA_ "U_C519_MCA_MY22_Tx" SG_ 103 Hlrspot3_Rq 0;
BA_ "U_C519_MCA_MY22_Rx" SG_ 102 Hllspot3TrgtUp_An_Rq 0;
BA_ "U_C519_MCA_MY22_Tx" SG_ 102 Hllspot3TrgtUp_An_Rq 0;
BA_ "GenSigStartValue" SG_ 102 Hllspot3TrgtUp_An_Rq 875;
BA_ "U_U611_U625_MY20_Phev_Tx" SG_ 102 Hllspot3TrgtUp_An_Rq 1;
BA_ "U_C519_MCA_MY22_Rx" SG_ 102 Hllspot3TrgtDown_An_Rq 0;
BA_ "U_C519_MCA_MY22_Tx" SG_ 102 Hllspot3TrgtDown_An_Rq 0;
BA_ "GenSigStartValue" SG_ 102 Hllspot3TrgtDown_An_Rq 875;
BA_ "U_U611_U625_MY20_Phev_Tx" SG_ 102 Hllspot3TrgtDown_An_Rq 1;
BA_ "U_C519_MCA_MY22_Rx" SG_ 102 Hllspot3TrgtLeft_An_Rq 0;
BA_ "U_C519_MCA_MY22_Tx" SG_ 102 Hllspot3TrgtLeft_An_Rq 0;
BA_ "GenSigStartValue" SG_ 102 Hllspot3TrgtLeft_An_Rq 875;
BA_ "U_U611_U625_MY20_Phev_Tx" SG_ 102 Hllspot3TrgtLeft_An_Rq 1;
BA_ "U_C519_MCA_MY22_Rx" SG_ 102 Hllspot3TrgtRght_An_Rq 0;
BA_ "U_C519_MCA_MY22_Tx" SG_ 102 Hllspot3TrgtRght_An_Rq 0;
BA_ "GenSigStartValue" SG_ 102 Hllspot3TrgtRght_An_Rq 875;
BA_ "U_U611_U625_MY20_Phev_Tx" SG_ 102 Hllspot3TrgtRght_An_Rq 1;
BA_ "U_C519_MCA_MY22_Rx" SG_ 102 Hllspot3V_T_Rq 0;
BA_ "U_C519_MCA_MY22_Tx" SG_ 102 Hllspot3V_T_Rq 0;
BA_ "U_U611_U625_MY20_Phev_Tx" SG_ 102 Hllspot3V_T_Rq 1;
BA_ "U_C519_MCA_MY22_Rx" SG_ 102 Hllspot3Brght_Pc_Rq 0;
BA_ "U_C519_MCA_MY22_Tx" SG_ 102 Hllspot3Brght_Pc_Rq 0;
BA_ "U_U611_U625_MY20_Phev_Tx" SG_ 102 Hllspot3Brght_Pc_Rq 1;
BA_ "U_C519_MCA_MY22_Rx" SG_ 102 Hllspot3_Rq 0;
BA_ "U_C519_MCA_MY22_Tx" SG_ 102 Hllspot3_Rq 0;
BA_ "U_C519_MCA_MY22_Rx" SG_ 101 Hlrspot2TrgtUp_An_Rq 0;
BA_ "U_C519_MCA_MY22_Tx" SG_ 101 Hlrspot2TrgtUp_An_Rq 0;
BA_ "GenSigStartValue" SG_ 101 Hlrspot2TrgtUp_An_Rq 875;
BA_ "U_U611_U625_MY20_Phev_Tx" SG_ 101 Hlrspot2TrgtUp_An_Rq 1;
BA_ "U_C519_MCA_MY22_Rx" SG_ 101 Hlrspot2TrgtDown_An_Rq 0;
BA_ "U_C519_MCA_MY22_Tx" SG_ 101 Hlrspot2TrgtDown_An_Rq 0;
BA_ "GenSigStartValue" SG_ 101 Hlrspot2TrgtDown_An_Rq 875;
BA_ "U_U611_U625_MY20_Phev_Tx" SG_ 101 Hlrspot2TrgtDown_An_Rq 1;
BA_ "U_C519_MCA_MY22_Rx" SG_ 101 Hlrspot2TrgtLeft_An_Rq 0;
BA_ "U_C519_MCA_MY22_Tx" SG_ 101 Hlrspot2TrgtLeft_An_Rq 0;
BA_ "GenSigStartValue" SG_ 101 Hlrspot2TrgtLeft_An_Rq 875;
BA_ "U_U611_U625_MY20_Phev_Tx" SG_ 101 Hlrspot2TrgtLeft_An_Rq 1;
BA_ "U_C519_MCA_MY22_Rx" SG_ 101 Hlrspot2TrgtRght_An_Rq 0;
BA_ "U_C519_MCA_MY22_Tx" SG_ 101 Hlrspot2TrgtRght_An_Rq 0;
BA_ "GenSigStartValue" SG_ 101 Hlrspot2TrgtRght_An_Rq 875;
BA_ "U_U611_U625_MY20_Phev_Tx" SG_ 101 Hlrspot2TrgtRght_An_Rq 1;
BA_ "U_C519_MCA_MY22_Rx" SG_ 101 Hlrspot2V_T_Rq 0;
BA_ "U_C519_MCA_MY22_Tx" SG_ 101 Hlrspot2V_T_Rq 0;
BA_ "U_U611_U625_MY20_Phev_Tx" SG_ 101 Hlrspot2V_T_Rq 1;
BA_ "U_C519_MCA_MY22_Rx" SG_ 101 Hlrspot2Brght_Pc_Rq 0;
BA_ "U_C519_MCA_MY22_Tx" SG_ 101 Hlrspot2Brght_Pc_Rq 0;
BA_ "U_U611_U625_MY20_Phev_Tx" SG_ 101 Hlrspot2Brght_Pc_Rq 1;
BA_ "U_C519_MCA_MY22_Rx" SG_ 101 Hlrspot2_Rq 0;
BA_ "U_C519_MCA_MY22_Tx" SG_ 101 Hlrspot2_Rq 0;
BA_ "U_C519_MCA_MY22_Rx" SG_ 100 Hllspot2TrgtUp_An_Rq 0;
BA_ "U_C519_MCA_MY22_Tx" SG_ 100 Hllspot2TrgtUp_An_Rq 0;
BA_ "U_U611_U625_MY20_Phev_Tx" SG_ 100 Hllspot2TrgtUp_An_Rq 1;
BA_ "GenSigStartValue" SG_ 100 Hllspot2TrgtUp_An_Rq 875;
BA_ "U_C519_MCA_MY22_Rx" SG_ 100 Hllspot2TrgtDown_An_Rq 0;
BA_ "U_C519_MCA_MY22_Tx" SG_ 100 Hllspot2TrgtDown_An_Rq 0;
BA_ "U_U611_U625_MY20_Phev_Tx" SG_ 100 Hllspot2TrgtDown_An_Rq 1;
BA_ "GenSigStartValue" SG_ 100 Hllspot2TrgtDown_An_Rq 875;
BA_ "U_C519_MCA_MY22_Rx" SG_ 100 Hllspot2TrgtLeft_An_Rq 0;
BA_ "U_C519_MCA_MY22_Tx" SG_ 100 Hllspot2TrgtLeft_An_Rq 0;
BA_ "U_U611_U625_MY20_Phev_Tx" SG_ 100 Hllspot2TrgtLeft_An_Rq 1;
BA_ "GenSigStartValue" SG_ 100 Hllspot2TrgtLeft_An_Rq 875;
BA_ "U_C519_MCA_MY22_Rx" SG_ 100 Hllspot2TrgtRght_An_Rq 0;
BA_ "U_C519_MCA_MY22_Tx" SG_ 100 Hllspot2TrgtRght_An_Rq 0;
BA_ "U_U611_U625_MY20_Phev_Tx" SG_ 100 Hllspot2TrgtRght_An_Rq 1;
BA_ "GenSigStartValue" SG_ 100 Hllspot2TrgtRght_An_Rq 875;
BA_ "U_C519_MCA_MY22_Rx" SG_ 100 Hllspot2V_T_Rq 0;
BA_ "U_C519_MCA_MY22_Tx" SG_ 100 Hllspot2V_T_Rq 0;
BA_ "U_U611_U625_MY20_Phev_Tx" SG_ 100 Hllspot2V_T_Rq 1;
BA_ "U_C519_MCA_MY22_Rx" SG_ 100 Hllspot2_Rq 0;
BA_ "U_C519_MCA_MY22_Tx" SG_ 100 Hllspot2_Rq 0;
BA_ "U_C519_MCA_MY22_Rx" SG_ 100 Hllspot2Brght_Pc_Rq 0;
BA_ "U_C519_MCA_MY22_Tx" SG_ 100 Hllspot2Brght_Pc_Rq 0;
BA_ "U_U611_U625_MY20_Phev_Tx" SG_ 100 Hllspot2Brght_Pc_Rq 1;
BA_ "GenSigSendType" SG_ 2015 TesterFunctionalReq 3;
BA_ "GenSigSendType" SG_ 1791 TesterPhysicalResLDCMB 3;
BA_ "GenSigSendType" SG_ 1790 TesterPhysicalResLDCMA 3;
BA_ "GenSigSendType" SG_ 1783 TesterPhysicalReqLDCMB 3;
BA_ "GenSigSendType" SG_ 1782 TesterPhysicalReqLDCMA 3;
BA_ "U_U611_U625_MY20_Phev_Tx" SG_ 96 Hllspot1Brght_Pc_Rq 1;
BA_ "U_U611_U625_MY20_Phev_Tx" SG_ 96 Hllspot1TrgtRght_An_Rq 1;
BA_ "GenSigStartValue" SG_ 96 Hllspot1TrgtRght_An_Rq 875;
BA_ "U_U611_U625_MY20_Phev_Tx" SG_ 96 Hllspot1TrgtLeft_An_Rq 1;
BA_ "GenSigStartValue" SG_ 96 Hllspot1TrgtLeft_An_Rq 875;
BA_ "U_U611_U625_MY20_Phev_Tx" SG_ 96 Hllspot1TrgtDown_An_Rq 1;
BA_ "GenSigStartValue" SG_ 96 Hllspot1TrgtDown_An_Rq 875;
BA_ "U_U611_U625_MY20_Phev_Tx" SG_ 96 Hllspot1TrgtUp_An_Rq 1;
BA_ "GenSigStartValue" SG_ 96 Hllspot1TrgtUp_An_Rq 875;
BA_ "U_U611_U625_MY20_Phev_Tx" SG_ 96 Hllspot1V_T_Rq 1;
BA_ "U_U611_U625_MY20_Phev_Tx" SG_ 89 HiBeamFadeVLeft_T_Rq 1;
BA_ "U_U611_U625_MY20_Phev_Tx" SG_ 89 HiBeamBrghtLeft_D_Rq 1;
BA_ "U_U611_U625_MY20_Phev_Tx" SG_ 89 HiBeamFadeVRight_T_Rq 1;
BA_ "U_U611_U625_MY20_Phev_Tx" SG_ 89 HiBeamBrghtRight_D_Rq 1;
BA_ "U_U554_MCA_MY22_Rx" SG_ 117 HlrHBFeedb_D_Stat 0;
BA_ "U_U554_MCA_MY22_Tx" SG_ 117 HlrHBFeedb_D_Stat 0;
BA_ "U_C519_MCA_MY22_Rx" SG_ 117 HlrHBSegFeedb_D_Stat 0;
BA_ "U_C519_MCA_MY22_Tx" SG_ 117 HlrHBSegFeedb_D_Stat 0;
BA_ "U_U611_U625_MY20_Phev_Tx" SG_ 117 Hlr_Temp_Stat 1;
BA_ "U_U611_U625_MY20_Phev_Tx" SG_ 117 Mdule1RightHl_side_Stat 1;
BA_ "U_U611_U625_MY20_Phev_Tx" SG_ 117 Mdule1RightHl_Com_Stat 1;
BA_ "U_U611_U625_MY20_Phev_Tx" SG_ 117 Mdule1Right_MPwr_B_Stat 1;
BA_ "U_U611_U625_MY20_Phev_Tx" SG_ 117 Mdule1Right_LB_Pwr_B_Stat 1;
BA_ "U_U611_U625_MY20_Phev_Tx" SG_ 117 Hlr_SM_Stat 1;
BA_ "U_U611_U625_MY20_Phev_Tx" SG_ 117 Hlr_SBL_Stat 1;
BA_ "U_U611_U625_MY20_Phev_Tx" SG_ 117 Hlr_Pixel_Stat 1;
BA_ "U_U611_U625_MY20_Phev_Tx" SG_ 117 Hlr_Fan_B_Stat 1;
BA_ "U_U611_U625_MY20_Phev_Tx" SG_ 117 Hlr_DRL_POS_Stat 1;
BA_ "U_U611_U625_MY20_Phev_Tx" SG_ 117 HeadLghtLvlRght_D_Stat 1;
BA_ "GenSigStartValue" SG_ 117 HeadLghtLvlRght_D_Stat 1;
BA_ "U_U611_U625_MY20_Phev_Tx" SG_ 117 HeadLghtLvlRght_No_Stat 1;
BA_ "U_U611_U625_MY20_Phev_Tx" SG_ 117 Mdule1RightFail_B_Stat 1;
BA_ "U_U611_U625_MY20_Phev_Tx" SG_ 117 Mdule1RightConfg_B_Stat 1;
BA_ "U_U554_MCA_MY22_Rx" SG_ 116 HllHBFeedb_D_Stat 0;
BA_ "U_U554_MCA_MY22_Tx" SG_ 116 HllHBFeedb_D_Stat 0;
BA_ "U_U611_U625_MY20_Phev_Tx" SG_ 116 HeadLghtLvlLeft_No_Stat 1;
BA_ "U_C519_MCA_MY22_Rx" SG_ 116 HllHBSegFeedb_D_Stat 0;
BA_ "U_C519_MCA_MY22_Tx" SG_ 116 HllHBSegFeedb_D_Stat 0;
BA_ "U_U611_U625_MY20_Phev_Tx" SG_ 116 Hll_Temp_Stat 1;
BA_ "U_U611_U625_MY20_Phev_Tx" SG_ 116 Mdule1LeftHl_side_Stat 1;
BA_ "U_U611_U625_MY20_Phev_Tx" SG_ 116 Mdule1LeftHl_Com_Stat 1;
BA_ "U_U611_U625_MY20_Phev_Tx" SG_ 116 Mdule1Left_MPwr_B_Stat 1;
BA_ "U_U611_U625_MY20_Phev_Tx" SG_ 116 Mdule1Left_LB_Pwr_B_Stat 1;
BA_ "U_U611_U625_MY20_Phev_Tx" SG_ 116 Hll_SM_Stat 1;
BA_ "U_U611_U625_MY20_Phev_Tx" SG_ 116 Hll_SBL_Stat 1;
BA_ "U_U611_U625_MY20_Phev_Tx" SG_ 116 Hll_Pixel_Stat 1;
BA_ "U_U611_U625_MY20_Phev_Tx" SG_ 116 Hll_Fan_B_Stat 1;
BA_ "U_U611_U625_MY20_Phev_Tx" SG_ 116 Hll_DRL_POS_Stat 1;
BA_ "U_U611_U625_MY20_Phev_Tx" SG_ 116 HeadLghtLvlLeft_D_Stat 1;
BA_ "GenSigStartValue" SG_ 116 HeadLghtLvlLeft_D_Stat 1;
BA_ "U_U611_U625_MY20_Phev_Tx" SG_ 116 Mdule1LeftFail_B_Stat 1;
BA_ "U_U611_U625_MY20_Phev_Tx" SG_ 116 Mdule1LeftConfg_B_Stat 1;
BA_ "U_U611_U625_MY20_Phev_Tx" SG_ 118 HeadLghtLvlRghtRef_D_Rq 1;
BA_ "U_U611_U625_MY20_Phev_Tx" SG_ 118 HeadLghtLvlLeftRef_D_Rq 1;
BA_ "U_U611_U625_MY20_Phev_Tx" SG_ 118 HeadLghtLvlRight_No_Rq 1;
BA_ "U_U611_U625_MY20_Phev_Tx" SG_ 118 HeadLghtLvlLeft_No_Rq 1;
BA_ "U_U611_U625_MY20_Phev_Tx" SG_ 85 HCMSleepyTime_B_Stat 1;
BA_ "GenSigSendType" SG_ 85 HCMSleepyTime_B_Stat 3;
BA_ "GenSigSendType" SG_ 85 Ignition_Status 3;
BA_ "U_U611_U625_MY20_Phev_Tx" SG_ 85 Ignition_Status 1;
BA_ "GenSigSendType" SG_ 85 PwPckTq_D_Stat 3;
BA_ "U_U611_U625_MY20_Phev_Tx" SG_ 85 PwPckTq_D_Stat 1;
BA_ "GenSigSendType" SG_ 85 ElPw_D_Stat 3;
BA_ "U_U611_U625_MY20_Phev_Tx" SG_ 85 ElPw_D_Stat 1;
BA_ "U_U611_U625_MY20_Phev_Tx" SG_ 98 Traffic_Style_Rq 1;
BA_ "U_U611_U625_MY20_Phev_Tx" SG_ 98 SwvlTrgtLeft_An_Rq 1;
BA_ "GenSigStartValue" SG_ 98 SwvlTrgtLeft_An_Rq 875;
BA_ "U_U611_U625_MY20_Phev_Tx" SG_ 98 SwvlTrgtRight_An_Rq 1;
BA_ "GenSigStartValue" SG_ 98 SwvlTrgtRight_An_Rq 875;
BA_ "U_U611_U625_MY20_Phev_Tx" SG_ 98 LowBeamLightClassL_T_Rq 1;
BA_ "U_U611_U625_MY20_Phev_Tx" SG_ 98 LowBeamLightClassR_T_Rq 1;
BA_ "U_U611_U625_MY20_Phev_Tx" SG_ 98 LowBeamLightClassL_D_Rq 1;
BA_ "U_U611_U625_MY20_Phev_Tx" SG_ 98 LowBeamLightClassR_D_Rq 1;
BA_ "U_U611_U625_MY20_Phev_Tx" SG_ 113 Slght5VRight_T_Rq 1;
BA_ "U_U611_U625_MY20_Phev_Tx" SG_ 113 Slght5BrghtRight_Pc_Rq 1;
BA_ "U_U611_U625_MY20_Phev_Tx" SG_ 113 Slght4VRight_T_Rq 1;
BA_ "U_U611_U625_MY20_Phev_Tx" SG_ 113 Slght4BrghtRight_Pc_Rq 1;
BA_ "U_U611_U625_MY20_Phev_Tx" SG_ 113 Slght3VRight_T_Rq 1;
BA_ "U_U611_U625_MY20_Phev_Tx" SG_ 113 Slght3BrghtRight_Pc_Rq 1;
BA_ "U_U611_U625_MY20_Phev_Tx" SG_ 113 Slght2VRight_T_Rq 1;
BA_ "U_U611_U625_MY20_Phev_Tx" SG_ 113 Slght2BrghtRight_Pc_Rq 1;
BA_ "U_U611_U625_MY20_Phev_Tx" SG_ 113 Slght1VRight_T_Rq 1;
BA_ "U_U611_U625_MY20_Phev_Tx" SG_ 113 Slght1BrghtRight_Pc_Rq 1;
BA_ "U_U611_U625_MY20_Phev_Tx" SG_ 112 Slght5VLeft_T_Rq 1;
BA_ "U_U611_U625_MY20_Phev_Tx" SG_ 112 Slght5BrghtLeft_Pc_Rq 1;
BA_ "U_U611_U625_MY20_Phev_Tx" SG_ 112 Slght4VLeft_T_Rq 1;
BA_ "U_U611_U625_MY20_Phev_Tx" SG_ 112 Slght4BrghtLeft_Pc_Rq 1;
BA_ "U_U611_U625_MY20_Phev_Tx" SG_ 112 Slght3VLeft_T_Rq 1;
BA_ "U_U611_U625_MY20_Phev_Tx" SG_ 112 Slght3BrghtLeft_Pc_Rq 1;
BA_ "U_U611_U625_MY20_Phev_Tx" SG_ 112 Slght2VLeft_T_Rq 1;
BA_ "U_U611_U625_MY20_Phev_Tx" SG_ 112 Slght2BrghtLeft_Pc_Rq 1;
BA_ "U_U611_U625_MY20_Phev_Tx" SG_ 112 Slght1VLeft_T_Rq 1;
BA_ "U_U611_U625_MY20_Phev_Tx" SG_ 112 Slght1BrghtLeft_Pc_Rq 1;
BA_ "U_U611_U625_MY20_Phev_Tx" SG_ 97 Hlrspot1TrgtUp_An_Rq 1;
BA_ "GenSigStartValue" SG_ 97 Hlrspot1TrgtUp_An_Rq 875;
BA_ "U_U611_U625_MY20_Phev_Tx" SG_ 97 Hlrspot1TrgtDown_An_Rq 1;
BA_ "GenSigStartValue" SG_ 97 Hlrspot1TrgtDown_An_Rq 875;
BA_ "U_U611_U625_MY20_Phev_Tx" SG_ 97 Hlrspot1TrgtLeft_An_Rq 1;
BA_ "GenSigStartValue" SG_ 97 Hlrspot1TrgtLeft_An_Rq 875;
BA_ "U_U611_U625_MY20_Phev_Tx" SG_ 97 Hlrspot1TrgtRght_An_Rq 1;
BA_ "GenSigStartValue" SG_ 97 Hlrspot1TrgtRght_An_Rq 875;
BA_ "U_U611_U625_MY20_Phev_Tx" SG_ 97 Hlrspot1V_T_Rq 1;
BA_ "U_U611_U625_MY20_Phev_Tx" SG_ 97 Hlrspot1Brght_Pc_Rq 1;
VAL_ 3221225472 HeadLghtLvlRghtRef_D_Rq 5 "Start partially reference 4" 4 "Start partially reference 3" 3 "Start partially reference 2" 2 "Lvl ref only" 1 "Start full rerence" 0 "No referencing action" ;
VAL_ 3221225472 HeadLghtLvlLeftRef_D_Rq 5 "Start partially reference 4" 4 "Start partially reference 3" 3 "Start partially reference 2" 2 "Lvl ref only" 1 "Start full rerence" 0 "No referencing action" ;
VAL_ 3221225472 HeadLghtLvlRight_No_Rq 4095 "Faulty" ;
VAL_ 3221225472 HeadLghtLvlLeft_No_Rq 4095 "Faulty" ;
VAL_ 3221225472 HeadLghtDblRght_No_Stat 4095 "Faulty" ;
VAL_ 3221225472 HeadLghtDblLeft_No_Stat 4095 "Faulty" ;
VAL_ 3221225472 HeadLghtDblRight_No_Rq 4095 "Faulty" ;
VAL_ 3221225472 HeadLghtDblLeft_No_Rq 4095 "Faulty" ;
VAL_ 3221225472 Hlr_Foregrd_Stat 1 "Foreground unit failure detected" 0 "Foreground unit status OK" ;
VAL_ 3221225472 Hll_Foregrd_Stat 1 "Foreground unit failure detected" 0 "Foreground unit status OK" ;
VAL_ 3221225472 Tracer_Turn_Actv_Rq 2 "SEQ B" 1 "SEQ A" 0 "Null" ;
VAL_ 3221225472 LowBeam_Stat 1 "Low Beam Active" 0 "Default" ;
VAL_ 3221225472 Turn_Actv_Rf_Rq 3 "SEQ" 2 "ON Cycle" 1 "OFF Cycle" 0 "Null" ;
VAL_ 3221225472 Turn_Actv_Lf_Rq 3 "SEQ" 2 "ON Cycle" 1 "OFF Cycle" 0 "Null" ;
VAL_ 3221225472 HeadLampLoFrOut_B_Stat 1 "Faulted" 0 "NotFaulted" ;
VAL_ 3221225472 TurnLampFrOut_B_Stat 1 "Out" 0 "Null" ;
VAL_ 3221225472 HeadLampLoFlOut_B_Stat 1 "Faulted" 0 "NotFaulted" ;
VAL_ 3221225472 TurnLampFlOut_B_Stat 1 "Out" 0 "Null" ;
VAL_ 784 TurnLampFrOut_B_Stat 1 "Out" 0 "Null" ;
VAL_ 784 HeadLampLoFrOut_B_Stat 1 "Faulted" 0 "NotFaulted" ;
VAL_ 768 TurnLampFlOut_B_Stat 1 "Out" 0 "Null" ;
VAL_ 768 HeadLampLoFlOut_B_Stat 1 "Faulted" 0 "NotFaulted" ;
VAL_ 800 TurnLghtRight_D_Rq 3 "Seq" 2 "On" 1 "Off" 0 "Null" ;
VAL_ 800 TurnLghtLeft_D_Rq 3 "Seq" 2 "On" 1 "Off" 0 "Null" ;
VAL_ 800 HeadLampLoFrOn_B_Stat 1 "Low" 0 "Not_Low" ;
VAL_ 800 HeadLampLoFlOn_B_Stat 1 "Low" 0 "Not_Low" ;
VAL_ 121 Hlr_DblMotor_Volt_D_Stat 3 "Normal Voltage Mode" 2 "Overvoltage Mode" 1 "Undervoltage Mode" 0 "Low Voltage Mode" ;
VAL_ 121 DblMtrRight_Motion_B_Stat 1 "Motor Moving" 0 "Motor Not Moving" ;
VAL_ 121 SwvlTrgtRight_An_D_Stat 2047 "Faulty" ;
VAL_ 121 Hlr_DblMotor_Temp_Stat 2 "Overtemperature" 1 "High Temperature" 0 "Status OK" ;
VAL_ 121 HeadLghtDblRght_D_Stat 2 "System_OK" 3 "Referencing" 1 "RefRequired" 0 "FAULT" ;
VAL_ 120 Hll_DblMotor_Volt_D_Stat 3 "Normal Voltage Mode" 2 "Overvoltage Mode" 1 "Undervoltage Mode" 0 "Low Voltage Mode" ;
VAL_ 120 DblMtrLeft_Motion_B_Stat 1 "Motor Moving" 0 "Motor Not Moving" ;
VAL_ 120 SwvlTrgtLeft_An_D_Stat 2047 "Faulty" ;
VAL_ 120 Hll_DblMotor_Temp_Stat 2 "Overtemperature" 1 "High Temperature" 0 "Status OK" ;
VAL_ 120 HeadLghtDbllLeft_D_Stat 2 "System_OK" 3 "Referencing" 1 "Ref Required" 0 "FAULT" ;
VAL_ 119 HeadLghtDblRghtRef_D_Rq 1 "Dbl ref only" 0 "No referencing action" ;
VAL_ 119 HeadLghtDblLeftRef_D_Rq 1 "Dbl ref only" 0 "No referencing action" ;
VAL_ 119 MtrSwvlTrgtRight_An_Rq 2047 "Faulty" ;
VAL_ 119 MtrSwvlTrgtLeft_An_Rq 2047 "Faulty" ;
VAL_ 80 DrlPos4_Actv_Rf_Rq 2 "DRL intensity" 1 "POS intensity" 0 "OFF" ;
VAL_ 80 DrlPos4_Actv_Lf_Rq 2 "DRL intensity" 1 "POS intensity" 0 "OFF" ;
VAL_ 80 DrlPos3_Actv_Rf_Rq 2 "DRL intensity" 1 "POS intensity" 0 "OFF" ;
VAL_ 80 DrlPos3_Actv_Lf_Rq 2 "DRL intensity" 1 "POS intensity" 0 "OFF" ;
VAL_ 80 HeadLghtSwtch_D_Stat 3 "Autolamp" 2 "Headlamp" 1 "Parklamp" 0 "Off" ;
VAL_ 80 ExtLghtFront_D_RqBody 3 "NotUsed" 2 "ON" 1 "OFF" 0 "Null" ;
VAL_ 80 Front_Fog_Actv_Rq 1 "Front Fog ON" 0 "Front Fog OFF" ;
VAL_ 80 WfSubstate_D_Stat 7 "IlluminatedExit" 6 "CourtesyLightingDelayExt" 5 "CourtesyLightingExtended" 4 "CourtesyLightingDelayAll" 3 "CourtesyLightingAll" 2 "IlluminatedEntry" 1 "Approach" 0 "NULL" ;
VAL_ 80 WfSuperstate_D_Stat 3 "RunStart" 2 "Farewell" 1 "Welcome" 0 "Null" ;
VAL_ 80 SideMarker_Actv_Rq 1 "ON" 0 "OFF" ;
VAL_ 80 DrlPos2_Actv_Rf_Rq 2 "DRL intensity" 1 "POS intensity" 0 "OFF" ;
VAL_ 80 DrlPos1_Actv_Rf_Rq 2 "DRL intensity" 1 "POS intensity" 0 "OFF" ;
VAL_ 80 DrlPos2_Actv_Lf_Rq 2 "DRL intensity" 1 "POS intensity" 0 "OFF" ;
VAL_ 80 DrlPos1_Actv_Lf_Rq 2 "DRL intensity" 1 "POS intensity" 0 "OFF" ;
VAL_ 103 Hlrspot3TrgtUp_An_Rq 2047 "Faulty" ;
VAL_ 103 Hlrspot3TrgtDown_An_Rq 2047 "Faulty" ;
VAL_ 103 Hlrspot3TrgtRght_An_Rq 2047 "Faulty" ;
VAL_ 103 Hlrspot3TrgtLeft_An_Rq 2047 "Faulty" ;
VAL_ 103 Hlrspot3Brght_Pc_Rq 31 "Faulty" ;
VAL_ 103 Hlrspot3_Rq 3 "Spot (only right side)" 2 "Spot (only left side)" 1 "Spot (both sides)" 0 "Not active" ;
VAL_ 102 Hllspot3TrgtUp_An_Rq 2047 "Faulty" ;
VAL_ 102 Hllspot3TrgtDown_An_Rq 2047 "Faulty" ;
VAL_ 102 Hllspot3TrgtLeft_An_Rq 2047 "Faulty" ;
VAL_ 102 Hllspot3TrgtRght_An_Rq 2047 "Faulty" ;
VAL_ 102 Hllspot3Brght_Pc_Rq 31 "Faulty" ;
VAL_ 102 Hllspot3_Rq 3 "Spot (only right side)" 2 "Spot (only left side)" 1 "Spot (both sides)" 0 "Not active" ;
VAL_ 101 Hlrspot2TrgtUp_An_Rq 2047 "Faulty" ;
VAL_ 101 Hlrspot2TrgtDown_An_Rq 2047 "Faulty" ;
VAL_ 101 Hlrspot2TrgtLeft_An_Rq 2047 "Faulty" ;
VAL_ 101 Hlrspot2TrgtRght_An_Rq 2047 "Faulty" ;
VAL_ 101 Hlrspot2Brght_Pc_Rq 31 "Faulty" ;
VAL_ 101 Hlrspot2_Rq 3 "Spot (only right side)" 2 "Spot (only left side)" 1 "Spot (both sides)" 0 "Not active" ;
VAL_ 100 Hllspot2TrgtUp_An_Rq 2047 "Faulty" ;
VAL_ 100 Hllspot2TrgtDown_An_Rq 2047 "Faulty" ;
VAL_ 100 Hllspot2TrgtLeft_An_Rq 2047 "Faulty" ;
VAL_ 100 Hllspot2TrgtRght_An_Rq 2047 "Faulty" ;
VAL_ 100 Hllspot2_Rq 3 "Spot (only right side)" 2 "Spot (only left side)" 1 "Spot (both sides)" 0 "Not active" ;
VAL_ 100 Hllspot2Brght_Pc_Rq 31 "Faulty" ;
VAL_ 96 Hllspot1_Rq 3 "Spot (only right side)" 2 "Spot (only left side)" 1 "Spot (both sides)" 0 "Not active" ;
VAL_ 96 Hllspot1Brght_Pc_Rq 31 "Faulty" ;
VAL_ 96 Hllspot1TrgtRght_An_Rq 2047 "Faulty" ;
VAL_ 96 Hllspot1TrgtLeft_An_Rq 2047 "Faulty" ;
VAL_ 96 Hllspot1TrgtDown_An_Rq 2047 "Faulty" ;
VAL_ 96 Hllspot1TrgtUp_An_Rq 2047 "Faulty" ;
VAL_ 89 HiBeamHWmde_SED_Rq 2 "Highway mode LHT" 1 "Highway mode RHT" 0 "No highway mode" ;
VAL_ 89 HBHL_Beam_D_Rq 7 "Placeholder" 6 "Placeholder" 5 "Placeholder" 4 "Wig Wag" 3 "Auto high beam" 2 "Manual high beam" 1 "Flash to pass" 0 "No High beam" ;
VAL_ 89 HiBeamBrghtLeft_D_Rq 31 "Faulty" ;
VAL_ 89 HiBeamBrghtRight_D_Rq 31 "Faulty" ;
VAL_ 117 HlrHBFeedb_D_Stat 5 "Spot (full fov spot)" 4 "Spot (only right side)" 3 "Spot (only left side)" 2 "Spot (both sides)" 1 "Full high beam" 0 "No high beam" ;
VAL_ 117 HlLoFrOnfdbck_B_Stat 1 "Low" 0 "Not_Low" ;
VAL_ 117 HlrHBSegFeedb_D_Stat 3 "At least one activated" 2 "Ramping up" 1 "Ramping down" 0 "All deactivated" ;
VAL_ 117 Hlr_Temp_Stat 1 "HL over temperature " 0 "HL temperature OK" ;
VAL_ 117 Mdule1RightHl_side_Stat 2 "LDM side detection failed." 1 "LDM detected right side." 0 "LDM detected left side." ;
VAL_ 117 Mdule1RightHl_Com_Stat 1 "Physical CAN bus com lost" 0 "Physical CAN bus OK" ;
VAL_ 117 Mdule1Right_MPwr_B_Stat 1 "LDM main power supply power lost" 0 "LDM main power supply available." ;
VAL_ 117 Mdule1Right_LB_Pwr_B_Stat 1 "LDM LB power supply power lost" 0 "LDM LB power supply available" ;
VAL_ 117 Hlr_SM_Stat 1 "SM unit failure detected" 0 "SM unit status OK" ;
VAL_ 117 Hlr_SBL_Stat 1 "SBL unit failure detected" 0 "SBL unit status OK" ;
VAL_ 117 Hlr_Pixel_Stat 1 "Pixel unit failure detected" 0 "Pixel unit status OK" ;
VAL_ 117 Hlr_Fan_B_Stat 1 "Fan failure detected" 0 "Fan status OK" ;
VAL_ 117 Hlr_DRL_POS_Stat 1 "DRL_POS unit failure detected" 0 "DRL_POS unit status OK" ;
VAL_ 117 Hlr_LvlMotor_Temp_Stat 2 "Overtemperature" 1 "High Temperature" 0 "Status OK" ;
VAL_ 117 HeadLghtLvlRght_D_Stat 2 "System_OK" 3 "Ref ongoing" 1 "Ref required" 0 "FAULT" ;
VAL_ 117 HeadLghtLvlRght_No_Stat 4095 "Faulty" ;
VAL_ 117 Mdule1RightFail_B_Stat 1 "LDM is NOK" 0 "LDM is OK" ;
VAL_ 117 Mdule1RightConfg_B_Stat 1 "FAULTY" 0 "OK" ;
VAL_ 116 HllHBFeedb_D_Stat 5 "Spot (all segments off)" 4 "Spot (right side)" 3 "Spot (left side)" 2 "Spot (both sides)" 1 "Full high beam" 0 "No high beam" ;
VAL_ 116 HlLoFlOnfdbck_B_Stat 1 "Low" 0 "Not_Low" ;
VAL_ 116 HeadLghtLvlLeft_No_Stat 4095 "Faulty" ;
VAL_ 116 HllHBSegFeedb_D_Stat 3 "At least one activated" 2 "Ramping up" 1 "Ramping down" 0 "All deactivated" ;
VAL_ 116 Hll_Temp_Stat 1 "HL over temperature " 0 "HL temperature OK" ;
VAL_ 116 Mdule1LeftHl_side_Stat 2 "LDM side detection failed." 1 "LDM detected right side." 0 "LDM detected left side." ;
VAL_ 116 Mdule1LeftHl_Com_Stat 1 "Physical CAN bus com lost" 0 "Physical CAN bus OK" ;
VAL_ 116 Mdule1Left_MPwr_B_Stat 1 "LDM main power supply power lost" 0 "LDM main power supply available." ;
VAL_ 116 Mdule1Left_LB_Pwr_B_Stat 1 "LDM LB power supply power lost" 0 "LDM LB power supply available" ;
VAL_ 116 Hll_SM_Stat 1 "SM unit failure detected" 0 "SM unit status OK" ;
VAL_ 116 Hll_SBL_Stat 1 "SBL unit failure detected" 0 "SBL unit status OK" ;
VAL_ 116 Hll_Pixel_Stat 1 "Pixel unit failure detected" 0 "Pixel unit status OK" ;
VAL_ 116 Hll_Fan_B_Stat 1 "Fan failure detected" 0 "Fan status OK" ;
VAL_ 116 Hll_DRL_POS_Stat 1 "DRL_POS unit failure detected" 0 "DRL_POS unit status OK" ;
VAL_ 116 Hll_LvlMotor_Temp_Stat 2 "Overtemperature" 1 "High Temperature" 0 "Status OK" ;
VAL_ 116 HeadLghtLvlLeft_D_Stat 2 "System_OK" 3 "Ref ongoing" 1 "Ref required" 0 "FAULT" ;
VAL_ 116 Mdule1LeftFail_B_Stat 1 "LDM is NOK" 0 "LDM is OK" ;
VAL_ 116 Mdule1LeftConfg_B_Stat 1 "FAULTY" 0 "OK" ;
VAL_ 118 HeadLghtLvlRghtRef_D_Rq 5 "Start partially reference 4" 4 "Start partially reference 3" 3 "Start partially reference 2" 2 "Lvl ref only" 1 "Start full rerence" 0 "No referencing action" ;
VAL_ 118 HeadLghtLvlLeftRef_D_Rq 5 "Start partially reference 4" 4 "Start partially reference 3" 3 "Start partially reference 2" 2 "Lvl ref only" 1 "Start full rerence" 0 "No referencing action" ;
VAL_ 118 HeadLghtLvlRight_No_Rq 4095 "Faulty" ;
VAL_ 118 HeadLghtLvlLeft_No_Rq 4095 "Faulty" ;
VAL_ 85 HCMSleepyTime_B_Stat 1 "Sleep_Imminent" 0 "Null" ;
VAL_ 85 Ignition_Status 15 "Invalid" 8 "Start" 4 "Run" 2 "Accessory" 1 "Off" 0 "Unknown" ;
VAL_ 85 PwPckTq_D_Stat 3 "PwPckOn_TqAvailable" 2 "PwPckStrtInProg_TqNotAvail" 1 "PwPckOn_TqNotAvailable" 0 "PwPckOff_TqNotAvailable" ;
VAL_ 85 ElPw_D_Stat 7 "NotUsed_3" 6 "NotUsed_2" 5 "NotUsed_1" 4 "Fault limited" 3 "LV event in progress" 2 "Not supported imminent" 1 "Supported" 0 "Not supported" ;
VAL_ 98 Traffic_Style_Rq 1 "RHT" 0 "LHT" ;
VAL_ 98 SwvlTrgtLeft_An_Rq 2047 "Faulty" ;
VAL_ 98 SwvlTrgtRight_An_Rq 2047 "Faulty" ;
VAL_ 98 LowBeamLightClassL_D_Rq 13 "Class W" 12 "Class E3" 11 "Class E2" 10 "Class E1" 9 "Class E" 8 "Class C4" 7 "Class C3" 6 "Class C2" 5 "Class C1" 4 "Class V3" 3 "Class V2" 2 "Class V1" 1 "Class V" 0 "Class C" ;
VAL_ 98 LowBeamLightClassR_D_Rq 13 "Class W" 12 "Class E3" 11 "Class E2" 10 "Class E1" 9 "Class E" 8 "Class C4" 7 "Class C3" 6 "Class C2" 5 "Class C1" 4 "Class V3" 3 "Class V2" 2 "Class V1" 1 "Class V" 0 "Class C" ;
VAL_ 97 Hlrspot1_Rq 3 "Spot (only right side)" 2 "Spot (only left side)" 1 "Spot (both sides)" 0 "Not active" ;
VAL_ 97 Hlrspot1TrgtUp_An_Rq 2047 "Faulty" ;
VAL_ 97 Hlrspot1TrgtDown_An_Rq 2047 "Faulty" ;
VAL_ 97 Hlrspot1TrgtLeft_An_Rq 2047 "Faulty" ;
VAL_ 97 Hlrspot1TrgtRght_An_Rq 2047 "Faulty" ;
VAL_ 97 Hlrspot1Brght_Pc_Rq 31 "Faulty" ;
